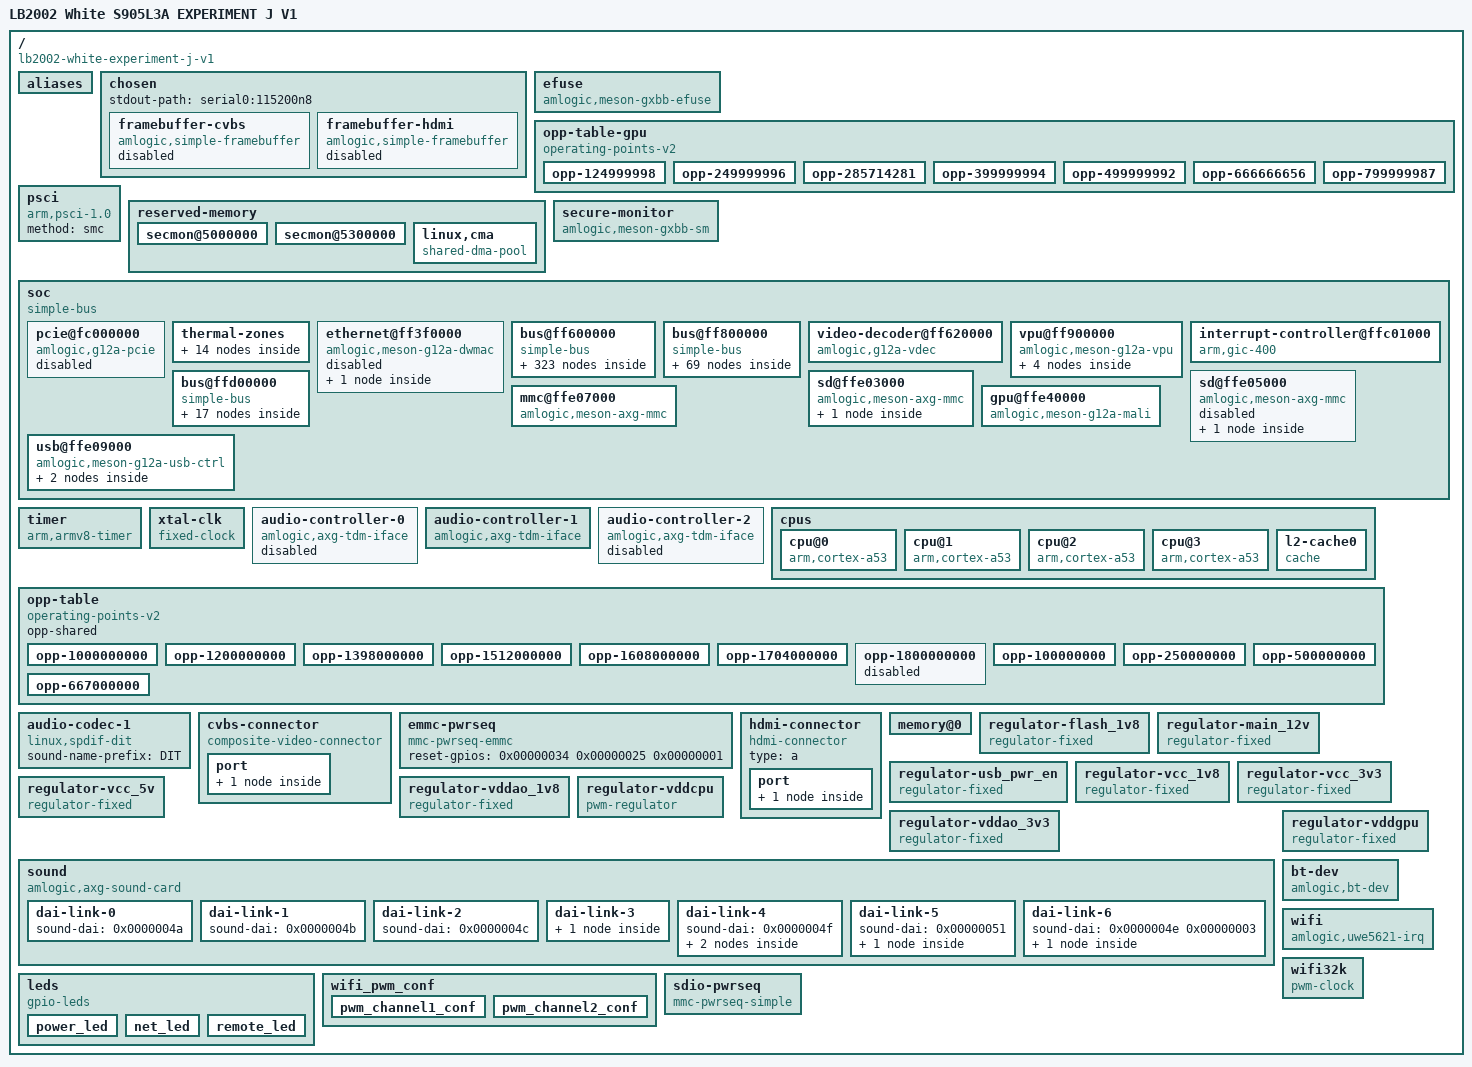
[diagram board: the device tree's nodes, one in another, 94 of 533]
/dts-v1/;
// version:		17
// last_comp_version:	16
// boot_cpuid_phys:	0x0

/ {
    interrupt-parent = <0x00000001>;
    #address-cells = <0x00000002>;
    #size-cells = <0x00000002>;
    model = "LB2002 White S905L3A EXPERIMENT J V1";
    compatible = "lb2002-white-experiment-j-v1", "lb2002-white-experiment-h-v1", "lb2002-white-experiment-g-v1", "m401a", "amlogic,g12a";
    amlogic-dt-id = "lb2002_m401a_experiment_j_v1_2g";
    aliases {
        ethernet0 = "/soc/ethernet@ff3f0000";
        serial1 = "/soc/bus@ffd00000/serial@24000";
        serial0 = "/soc/bus@ff800000/serial@3000";
        mmc2 = "/soc/mmc@ffe07000";
        mmc0 = "/soc/sd@ffe03000";
        mmc1 = "/soc/sd@ffe05000";
        sd_emmc_a = "/soc/sd@ffe03000";
        sd_emmc_b = "/soc/sd@ffe05000";
    };
    chosen {
        #address-cells = <0x00000002>;
        #size-cells = <0x00000002>;
        ranges;
        stdout-path = "serial0:115200n8";
        framebuffer-cvbs {
            compatible = "amlogic,simple-framebuffer", "simple-framebuffer";
            amlogic,pipeline = "vpu-cvbs";
            clocks = <0x00000002 0x000000a8 0x00000002 0x00000035 0x00000002 0x0000003a>;
            status = "disabled";
            power-domains = <0x00000003 0x00000000>;
            phandle = <0x00000053>;
        };
        framebuffer-hdmi {
            compatible = "amlogic,simple-framebuffer", "simple-framebuffer";
            amlogic,pipeline = "vpu-hdmi";
            clocks = <0x00000002 0x000000a8 0x00000002 0x00000035 0x00000002 0x0000003a>;
            status = "disabled";
            power-domains = <0x00000003 0x00000000>;
            phandle = <0x00000054>;
        };
    };
    efuse {
        compatible = "amlogic,meson-gxbb-efuse";
        clocks = <0x00000002 0x0000006a>;
        #address-cells = <0x00000001>;
        #size-cells = <0x00000001>;
        read-only;
        secure-monitor = <0x00000004>;
        phandle = <0x00000055>;
    };
    opp-table-gpu {
        compatible = "operating-points-v2";
        phandle = <0x00000040>;
        opp-124999998 {
            opp-hz = <0x00000000 0x0773593e>;
            opp-microvolt = <0x000c3500>;
        };
        opp-249999996 {
            opp-hz = <0x00000000 0x0ee6b27c>;
            opp-microvolt = <0x000c3500>;
        };
        opp-285714281 {
            opp-hz = <0x00000000 0x1107a769>;
            opp-microvolt = <0x000c3500>;
        };
        opp-399999994 {
            opp-hz = <0x00000000 0x17d783fa>;
            opp-microvolt = <0x000c3500>;
        };
        opp-499999992 {
            opp-hz = <0x00000000 0x1dcd64f8>;
            opp-microvolt = <0x000c3500>;
        };
        opp-666666656 {
            opp-hz = <0x00000000 0x27bc86a0>;
            opp-microvolt = <0x000c3500>;
        };
        opp-799999987 {
            opp-hz = <0x00000000 0x2faf07f3>;
            opp-microvolt = <0x000c3500>;
        };
    };
    psci {
        compatible = "arm,psci-1.0";
        method = "smc";
    };
    reserved-memory {
        #address-cells = <0x00000002>;
        #size-cells = <0x00000002>;
        ranges;
        secmon@5000000 {
            reg = <0x00000000 0x05000000 0x00000000 0x00300000>;
            no-map;
            phandle = <0x00000056>;
        };
        secmon@5300000 {
            reg = <0x00000000 0x05300000 0x00000000 0x02000000>;
            no-map;
            phandle = <0x00000057>;
        };
        linux,cma {
            compatible = "shared-dma-pool";
            reusable;
            size = <0x00000000 0x10000000>;
            alignment = <0x00000000 0x00400000>;
            linux,cma-default;
        };
    };
    secure-monitor {
        compatible = "amlogic,meson-gxbb-sm";
        phandle = <0x00000004>;
    };
    soc {
        compatible = "simple-bus";
        #address-cells = <0x00000002>;
        #size-cells = <0x00000002>;
        ranges;
        pcie@fc000000 {
            compatible = "amlogic,g12a-pcie", "snps,dw-pcie";
            reg = <0x00000000 0xfc000000 0x00000000 0x00400000 0x00000000 0xff648000 0x00000000 0x00002000 0x00000000 0xfc400000 0x00000000 0x00200000>;
            reg-names = "elbi", "cfg", "config";
            interrupts = <0x00000000 0x000000dd 0x00000004>;
            #interrupt-cells = <0x00000001>;
            interrupt-map-mask = <0x00000000 0x00000000 0x00000000 0x00000000>;
            interrupt-map = <0x00000000 0x00000000 0x00000000 0x00000000 0x00000001 0x00000000 0x000000df 0x00000004>;
            bus-range = <0x00000000 0x000000ff>;
            #address-cells = <0x00000003>;
            #size-cells = <0x00000002>;
            device_type = "pci";
            ranges = <0x81000000 0x00000000 0x00000000 0x00000000 0xfc600000 0x00000000 0x00100000 0x82000000 0x00000000 0xfc700000 0x00000000 0xfc700000 0x00000000 0x01900000>;
            clocks = <0x00000002 0x00000030 0x00000002 0x0000002d 0x00000002 0x000000c9>;
            clock-names = "general", "pclk", "port";
            resets = <0x00000005 0x0000000c 0x00000005 0x0000000f>;
            reset-names = "port", "apb";
            num-lanes = <0x00000001>;
            phys = <0x00000006 0x00000002>;
            phy-names = "pcie";
            status = "disabled";
            phandle = <0x00000058>;
        };
        thermal-zones {
            cpu-thermal {
                polling-delay = <0x000003e8>;
                polling-delay-passive = <0x00000064>;
                thermal-sensors = <0x00000007>;
                phandle = <0x00000059>;
                trips {
                    cpu-passive {
                        temperature = <0x00014c08>;
                        hysteresis = <0x000007d0>;
                        type = "passive";
                        phandle = <0x00000008>;
                    };
                    cpu-hot {
                        temperature = <0x00017318>;
                        hysteresis = <0x000007d0>;
                        type = "hot";
                        phandle = <0x0000000d>;
                    };
                    cpu-critical {
                        temperature = <0x0001adb0>;
                        hysteresis = <0x000007d0>;
                        type = "critical";
                        phandle = <0x0000005a>;
                    };
                };
                cooling-maps {
                    map0 {
                        trip = <0x00000008>;
                        cooling-device = <0x00000009 0xffffffff 0xffffffff 0x0000000a 0xffffffff 0xffffffff 0x0000000b 0xffffffff 0xffffffff 0x0000000c 0xffffffff 0xffffffff>;
                    };
                    map1 {
                        trip = <0x0000000d>;
                        cooling-device = <0x00000009 0xffffffff 0xffffffff 0x0000000a 0xffffffff 0xffffffff 0x0000000b 0xffffffff 0xffffffff 0x0000000c 0xffffffff 0xffffffff>;
                    };
                };
            };
            ddr-thermal {
                polling-delay = <0x000003e8>;
                polling-delay-passive = <0x00000064>;
                thermal-sensors = <0x0000000e>;
                phandle = <0x0000005b>;
                trips {
                    ddr-passive {
                        temperature = <0x00014c08>;
                        hysteresis = <0x000007d0>;
                        type = "passive";
                        phandle = <0x0000000f>;
                    };
                    ddr-critical {
                        temperature = <0x0001adb0>;
                        hysteresis = <0x000007d0>;
                        type = "critical";
                        phandle = <0x0000005c>;
                    };
                };
                cooling-maps {
                    map {
                        trip = <0x0000000f>;
                        cooling-device = <0x00000010 0xffffffff 0xffffffff>;
                    };
                };
            };
        };
        ethernet@ff3f0000 {
            compatible = "amlogic,meson-g12a-dwmac", "snps,dwmac-3.70a", "snps,dwmac";
            reg = <0x00000000 0xff3f0000 0x00000000 0x00010000 0x00000000 0xff634540 0x00000000 0x00000008>;
            interrupts = <0x00000000 0x00000008 0x00000004>;
            interrupt-names = "macirq";
            clocks = <0x00000002 0x00000026 0x00000002 0x00000002 0x00000002 0x0000000d 0x00000002 0x00000002>;
            clock-names = "stmmaceth", "clkin0", "clkin1", "timing-adjustment";
            rx-fifo-depth = <0x00001000>;
            tx-fifo-depth = <0x00000800>;
            status = "disabled";
            power-domains = <0x00000003 0x00000001>;
            phy-handle = <0x00000011>;
            phy-mode = "rmii";
            phandle = <0x0000005d>;
            mdio {
                #address-cells = <0x00000001>;
                #size-cells = <0x00000000>;
                compatible = "snps,dwmac-mdio";
                phandle = <0x0000001b>;
            };
        };
        bus@ff600000 {
            compatible = "simple-bus";
            reg = <0x00000000 0xff600000 0x00000000 0x00200000>;
            #address-cells = <0x00000002>;
            #size-cells = <0x00000002>;
            ranges = <0x00000000 0x00000000 0x00000000 0xff600000 0x00000000 0x00200000>;
            phandle = <0x0000005e>;
            hdmi-tx@0 {
                compatible = "amlogic,meson-g12a-dw-hdmi";
                reg = <0x00000000 0x00000000 0x00000000 0x00010000>;
                interrupts = <0x00000000 0x00000039 0x00000001>;
                resets = <0x00000005 0x00000013 0x00000005 0x00000042 0x00000005 0x0000004f>;
                reset-names = "hdmitx_apb", "hdmitx", "hdmitx_phy";
                clocks = <0x00000002 0x000000a8 0x00000002 0x00000035 0x00000002 0x0000003a>;
                clock-names = "isfr", "iahb", "venci";
                #address-cells = <0x00000001>;
                #size-cells = <0x00000000>;
                #sound-dai-cells = <0x00000000>;
                status = "okay";
                pinctrl-0 = <0x00000012 0x00000013>;
                pinctrl-names = "default";
                hdmi-supply = <0x00000014>;
                phandle = <0x00000022>;
                port@0 {
                    reg = <0x00000000>;
                    phandle = <0x0000005f>;
                    endpoint {
                        remote-endpoint = <0x00000015>;
                        phandle = <0x00000029>;
                    };
                };
                port@1 {
                    reg = <0x00000001>;
                    phandle = <0x00000060>;
                    endpoint {
                        remote-endpoint = <0x00000016>;
                        phandle = <0x00000046>;
                    };
                };
            };
            bus@30000 {
                compatible = "simple-bus";
                reg = <0x00000000 0x00030000 0x00000000 0x00002000>;
                #address-cells = <0x00000002>;
                #size-cells = <0x00000002>;
                ranges = <0x00000000 0x00000000 0x00000000 0x00030000 0x00000000 0x00002000>;
                phandle = <0x00000061>;
                rng@218 {
                    compatible = "amlogic,meson-rng";
                    reg = <0x00000000 0x00000218 0x00000000 0x00000004>;
                    clocks = <0x00000002 0x0000001b>;
                    clock-names = "core";
                    phandle = <0x00000062>;
                };
            };
            audio-controller@32000 {
                compatible = "amlogic,t9015";
                reg = <0x00000000 0x00032000 0x00000000 0x00000014>;
                #sound-dai-cells = <0x00000000>;
                sound-name-prefix = "ACODEC";
                clocks = <0x00000002 0x00000024>;
                clock-names = "pclk";
                resets = <0x00000005 0x0000003d>;
                status = "disabled";
                phandle = <0x00000063>;
            };
            bus@34400 {
                compatible = "simple-bus";
                reg = <0x00000000 0x00034400 0x00000000 0x00000400>;
                #address-cells = <0x00000002>;
                #size-cells = <0x00000002>;
                ranges = <0x00000000 0x00000000 0x00000000 0x00034400 0x00000000 0x00000400>;
                phandle = <0x00000064>;
                pinctrl@40 {
                    compatible = "amlogic,meson-g12a-periphs-pinctrl";
                    #address-cells = <0x00000002>;
                    #size-cells = <0x00000002>;
                    ranges;
                    phandle = <0x00000017>;
                    bank@40 {
                        reg = <0x00000000 0x00000040 0x00000000 0x0000004c 0x00000000 0x000000e8 0x00000000 0x00000018 0x00000000 0x00000120 0x00000000 0x00000018 0x00000000 0x000002c0 0x00000000 0x00000040 0x00000000 0x00000340 0x00000000 0x0000001c>;
                        reg-names = "gpio", "pull", "pull-enable", "mux", "ds";
                        gpio-controller;
                        #gpio-cells = <0x00000002>;
                        gpio-ranges = <0x00000017 0x00000000 0x00000000 0x00000056>;
                        phandle = <0x00000034>;
                    };
                    cec_ao_a_h {
                        phandle = <0x00000021>;
                        mux {
                            groups = "cec_ao_a_h";
                            function = "cec_ao_a_h";
                            bias-disable;
                        };
                    };
                    cec_ao_b_h {
                        phandle = <0x00000023>;
                        mux {
                            groups = "cec_ao_b_h";
                            function = "cec_ao_b_h";
                            bias-disable;
                        };
                    };
                    emmc-ctrl {
                        phandle = <0x00000036>;
                        mux-0 {
                            groups = "emmc_cmd";
                            function = "emmc";
                            bias-pull-up;
                            drive-strength-microamp = <0x00000fa0>;
                        };
                        mux-1 {
                            groups = "emmc_clk";
                            function = "emmc";
                            bias-disable;
                            drive-strength-microamp = <0x00000fa0>;
                        };
                    };
                    emmc-data-4b {
                        phandle = <0x00000065>;
                        mux-0 {
                            groups = "emmc_nand_d0", "emmc_nand_d1", "emmc_nand_d2", "emmc_nand_d3";
                            function = "emmc";
                            bias-pull-up;
                            drive-strength-microamp = <0x00000fa0>;
                        };
                    };
                    emmc-data-8b {
                        phandle = <0x00000037>;
                        mux-0 {
                            groups = "emmc_nand_d0", "emmc_nand_d1", "emmc_nand_d2", "emmc_nand_d3", "emmc_nand_d4", "emmc_nand_d5", "emmc_nand_d6", "emmc_nand_d7";
                            function = "emmc";
                            bias-pull-up;
                            drive-strength-microamp = <0x00000fa0>;
                        };
                    };
                    emmc-ds {
                        phandle = <0x00000038>;
                        mux {
                            groups = "emmc_nand_ds";
                            function = "emmc";
                            bias-pull-down;
                            drive-strength-microamp = <0x00000fa0>;
                        };
                    };
                    emmc_clk_gate {
                        phandle = <0x00000039>;
                        mux {
                            groups = "BOOT_8";
                            function = "gpio_periphs";
                            bias-pull-down;
                            drive-strength-microamp = <0x00000fa0>;
                        };
                    };
                    hdmitx_ddc {
                        phandle = <0x00000013>;
                        mux {
                            groups = "hdmitx_sda", "hdmitx_sck";
                            function = "hdmitx";
                            bias-disable;
                            drive-strength-microamp = <0x00000fa0>;
                        };
                    };
                    hdmitx_hpd {
                        phandle = <0x00000012>;
                        mux {
                            groups = "hdmitx_hpd_in";
                            function = "hdmitx";
                            bias-disable;
                        };
                    };
                    i2c0-sda-c {
                        phandle = <0x00000066>;
                        mux {
                            groups = "i2c0_sda_c";
                            function = "i2c0";
                            bias-disable;
                            drive-strength-microamp = <0x00000bb8>;
                        };
                    };
                    i2c0-sck-c {
                        phandle = <0x00000067>;
                        mux {
                            groups = "i2c0_sck_c";
                            function = "i2c0";
                            bias-disable;
                            drive-strength-microamp = <0x00000bb8>;
                        };
                    };
                    i2c0-sda-z0 {
                        phandle = <0x0000002e>;
                        mux {
                            groups = "i2c0_sda_z0";
                            function = "i2c0";
                            bias-disable;
                            drive-strength-microamp = <0x00000bb8>;
                        };
                    };
                    i2c0-sck-z1 {
                        phandle = <0x0000002f>;
                        mux {
                            groups = "i2c0_sck_z1";
                            function = "i2c0";
                            bias-disable;
                            drive-strength-microamp = <0x00000bb8>;
                        };
                    };
                    i2c0-sda-z7 {
                        phandle = <0x00000068>;
                        mux {
                            groups = "i2c0_sda_z7";
                            function = "i2c0";
                            bias-disable;
                            drive-strength-microamp = <0x00000bb8>;
                        };
                    };
                    i2c0-sda-z8 {
                        phandle = <0x00000069>;
                        mux {
                            groups = "i2c0_sda_z8";
                            function = "i2c0";
                            bias-disable;
                            drive-strength-microamp = <0x00000bb8>;
                        };
                    };
                    i2c1-sda-x {
                        phandle = <0x0000006a>;
                        mux {
                            groups = "i2c1_sda_x";
                            function = "i2c1";
                            bias-disable;
                            drive-strength-microamp = <0x00000bb8>;
                        };
                    };
                    i2c1-sck-x {
                        phandle = <0x0000006b>;
                        mux {
                            groups = "i2c1_sck_x";
                            function = "i2c1";
                            bias-disable;
                            drive-strength-microamp = <0x00000bb8>;
                        };
                    };
                    i2c1-sda-h2 {
                        phandle = <0x0000006c>;
                        mux {
                            groups = "i2c1_sda_h2";
                            function = "i2c1";
                            bias-disable;
                            drive-strength-microamp = <0x00000bb8>;
                        };
                    };
                    i2c1-sck-h3 {
                        phandle = <0x0000006d>;
                        mux {
                            groups = "i2c1_sck_h3";
                            function = "i2c1";
                            bias-disable;
                            drive-strength-microamp = <0x00000bb8>;
                        };
                    };
                    i2c1-sda-h6 {
                        phandle = <0x0000006e>;
                        mux {
                            groups = "i2c1_sda_h6";
                            function = "i2c1";
                            bias-disable;
                            drive-strength-microamp = <0x00000bb8>;
                        };
                    };
                    i2c1-sck-h7 {
                        phandle = <0x0000006f>;
                        mux {
                            groups = "i2c1_sck_h7";
                            function = "i2c1";
                            bias-disable;
                            drive-strength-microamp = <0x00000bb8>;
                        };
                    };
                    i2c2-sda-x {
                        phandle = <0x00000070>;
                        mux {
                            groups = "i2c2_sda_x";
                            function = "i2c2";
                            bias-disable;
                            drive-strength-microamp = <0x00000bb8>;
                        };
                    };
                    i2c2-sck-x {
                        phandle = <0x00000071>;
                        mux {
                            groups = "i2c2_sck_x";
                            function = "i2c2";
                            bias-disable;
                            drive-strength-microamp = <0x00000bb8>;
                        };
                    };
                    i2c2-sda-z {
                        phandle = <0x0000002c>;
                        mux {
                            groups = "i2c2_sda_z";
                            function = "i2c2";
                            bias-disable;
                            drive-strength-microamp = <0x00000bb8>;
                        };
                    };
                    i2c2-sck-z {
                        phandle = <0x0000002d>;
                        mux {
                            groups = "i2c2_sck_z";
                            function = "i2c2";
                            bias-disable;
                            drive-strength-microamp = <0x00000bb8>;
                        };
                    };
                    i2c3-sda-h {
                        phandle = <0x00000072>;
                        mux {
                            groups = "i2c3_sda_h";
                            function = "i2c3";
                            bias-disable;
                            drive-strength-microamp = <0x00000bb8>;
                        };
                    };
                    i2c3-sck-h {
                        phandle = <0x00000073>;
                        mux {
                            groups = "i2c3_sck_h";
                            function = "i2c3";
                            bias-disable;
                            drive-strength-microamp = <0x00000bb8>;
                        };
                    };
                    i2c3-sda-a {
                        phandle = <0x0000002a>;
                        mux {
                            groups = "i2c3_sda_a";
                            function = "i2c3";
                            bias-disable;
                            drive-strength-microamp = <0x00000bb8>;
                        };
                    };
                    i2c3-sck-a {
                        phandle = <0x0000002b>;
                        mux {
                            groups = "i2c3_sck_a";
                            function = "i2c3";
                            bias-disable;
                            drive-strength-microamp = <0x00000bb8>;
                        };
                    };
                    mclk0-a {
                        phandle = <0x00000074>;
                        mux {
                            groups = "mclk0_a";
                            function = "mclk0";
                            bias-disable;
                            drive-strength-microamp = <0x00000bb8>;
                        };
                    };
                    mclk1-a {
                        phandle = <0x00000075>;
                        mux {
                            groups = "mclk1_a";
                            function = "mclk1";
                            bias-disable;
                            drive-strength-microamp = <0x00000bb8>;
                        };
                    };
                    mclk1-x {
                        phandle = <0x00000076>;
                        mux {
                            groups = "mclk1_x";
                            function = "mclk1";
                            bias-disable;
                            drive-strength-microamp = <0x00000bb8>;
                        };
                    };
                    mclk1-z {
                        phandle = <0x00000077>;
                        mux {
                            groups = "mclk1_z";
                            function = "mclk1";
                            bias-disable;
                            drive-strength-microamp = <0x00000bb8>;
                        };
                    };
                    nor {
                        phandle = <0x00000078>;
                        mux {
                            groups = "nor_d", "nor_q", "nor_c", "nor_cs";
                            function = "nor";
                            bias-disable;
                        };
                    };
                    pdm-din0-a {
                        phandle = <0x00000079>;
                        mux {
                            groups = "pdm_din0_a";
                            function = "pdm";
                            bias-disable;
                        };
                    };
                    pdm-din0-c {
                        phandle = <0x0000007a>;
                        mux {
                            groups = "pdm_din0_c";
                            function = "pdm";
                            bias-disable;
                        };
                    };
                    pdm-din0-x {
                        phandle = <0x0000007b>;
                        mux {
                            groups = "pdm_din0_x";
                            function = "pdm";
                            bias-disable;
                        };
                    };
                    pdm-din0-z {
                        phandle = <0x0000007c>;
                        mux {
                            groups = "pdm_din0_z";
                            function = "pdm";
                            bias-disable;
                        };
                    };
                    pdm-din1-a {
                        phandle = <0x0000007d>;
                        mux {
                            groups = "pdm_din1_a";
                            function = "pdm";
                            bias-disable;
                        };
                    };
                    pdm-din1-c {
                        phandle = <0x0000007e>;
                        mux {
                            groups = "pdm_din1_c";
                            function = "pdm";
                            bias-disable;
                        };
                    };
                    pdm-din1-x {
                        phandle = <0x0000007f>;
                        mux {
                            groups = "pdm_din1_x";
                            function = "pdm";
                            bias-disable;
                        };
                    };
                    pdm-din1-z {
                        phandle = <0x00000080>;
                        mux {
                            groups = "pdm_din1_z";
                            function = "pdm";
                            bias-disable;
                        };
                    };
                    pdm-din2-a {
                        phandle = <0x00000081>;
                        mux {
                            groups = "pdm_din2_a";
                            function = "pdm";
                            bias-disable;
                        };
                    };
                    pdm-din2-c {
                        phandle = <0x00000082>;
                        mux {
                            groups = "pdm_din2_c";
                            function = "pdm";
                            bias-disable;
                        };
                    };
                    pdm-din2-x {
                        phandle = <0x00000083>;
                        mux {
                            groups = "pdm_din2_x";
                            function = "pdm";
                            bias-disable;
                        };
                    };
                    pdm-din2-z {
                        phandle = <0x00000084>;
                        mux {
                            groups = "pdm_din2_z";
                            function = "pdm";
                            bias-disable;
                        };
                    };
                    pdm-din3-a {
                        phandle = <0x00000085>;
                        mux {
                            groups = "pdm_din3_a";
                            function = "pdm";
                            bias-disable;
                        };
                    };
                    pdm-din3-c {
                        phandle = <0x00000086>;
                        mux {
                            groups = "pdm_din3_c";
                            function = "pdm";
                            bias-disable;
                        };
                    };
                    pdm-din3-x {
                        phandle = <0x00000087>;
                        mux {
                            groups = "pdm_din3_x";
                            function = "pdm";
                            bias-disable;
                        };
                    };
                    pdm-din3-z {
                        phandle = <0x00000088>;
                        mux {
                            groups = "pdm_din3_z";
                            function = "pdm";
                            bias-disable;
                        };
                    };
                    pdm-dclk-a {
                        phandle = <0x00000089>;
                        mux {
                            groups = "pdm_dclk_a";
                            function = "pdm";
                            bias-disable;
                            drive-strength-microamp = <0x000001f4>;
                        };
                    };
                    pdm-dclk-c {
                        phandle = <0x0000008a>;
                        mux {
                            groups = "pdm_dclk_c";
                            function = "pdm";
                            bias-disable;
                            drive-strength-microamp = <0x000001f4>;
                        };
                    };
                    pdm-dclk-x {
                        phandle = <0x0000008b>;
                        mux {
                            groups = "pdm_dclk_x";
                            function = "pdm";
                            bias-disable;
                            drive-strength-microamp = <0x000001f4>;
                        };
                    };
                    pdm-dclk-z {
                        phandle = <0x0000008c>;
                        mux {
                            groups = "pdm_dclk_z";
                            function = "pdm";
                            bias-disable;
                            drive-strength-microamp = <0x000001f4>;
                        };
                    };
                    pwm-a {
                        phandle = <0x0000008d>;
                        mux {
                            groups = "pwm_a";
                            function = "pwm_a";
                            bias-disable;
                        };
                    };
                    pwm-b-x7 {
                        phandle = <0x0000008e>;
                        mux {
                            groups = "pwm_b_x7";
                            function = "pwm_b";
                            bias-disable;
                        };
                    };
                    pwm-b-x19 {
                        phandle = <0x0000008f>;
                        mux {
                            groups = "pwm_b_x19";
                            function = "pwm_b";
                            bias-disable;
                        };
                    };
                    pwm-c-c {
                        phandle = <0x00000090>;
                        mux {
                            groups = "pwm_c_c";
                            function = "pwm_c";
                            bias-disable;
                        };
                    };
                    pwm-c-x5 {
                        phandle = <0x00000091>;
                        mux {
                            groups = "pwm_c_x5";
                            function = "pwm_c";
                            bias-disable;
                        };
                    };
                    pwm-c-x8 {
                        phandle = <0x00000092>;
                        mux {
                            groups = "pwm_c_x8";
                            function = "pwm_c";
                            bias-disable;
                        };
                    };
                    pwm-d-x3 {
                        phandle = <0x00000093>;
                        mux {
                            groups = "pwm_d_x3";
                            function = "pwm_d";
                            bias-disable;
                        };
                    };
                    pwm-d-x6 {
                        phandle = <0x00000094>;
                        mux {
                            groups = "pwm_d_x6";
                            function = "pwm_d";
                            bias-disable;
                        };
                    };
                    pwm-e {
                        phandle = <0x00000095>;
                        mux {
                            groups = "pwm_e";
                            function = "pwm_e";
                            bias-disable;
                        };
                    };
                    pwm-f-x {
                        phandle = <0x00000096>;
                        mux {
                            groups = "pwm_f_x";
                            function = "pwm_f";
                            bias-disable;
                        };
                    };
                    pwm-f-h {
                        phandle = <0x00000097>;
                        mux {
                            groups = "pwm_f_h";
                            function = "pwm_f";
                            bias-disable;
                        };
                    };
                    sdcard_c {
                        phandle = <0x00000032>;
                        mux-0 {
                            groups = "sdcard_d0_c", "sdcard_d1_c", "sdcard_d2_c", "sdcard_d3_c", "sdcard_cmd_c";
                            function = "sdcard";
                            bias-pull-up;
                            drive-strength-microamp = <0x00000fa0>;
                        };
                        mux-1 {
                            groups = "sdcard_clk_c";
                            function = "sdcard";
                            bias-disable;
                            drive-strength-microamp = <0x00000fa0>;
                        };
                    };
                    sdcard_clk_gate_c {
                        phandle = <0x00000033>;
                        mux {
                            groups = "GPIOC_4";
                            function = "gpio_periphs";
                            bias-pull-down;
                            drive-strength-microamp = <0x00000fa0>;
                        };
                    };
                    sdcard_z {
                        phandle = <0x00000098>;
                        mux-0 {
                            groups = "sdcard_d0_z", "sdcard_d1_z", "sdcard_d2_z", "sdcard_d3_z", "sdcard_cmd_z";
                            function = "sdcard";
                            bias-pull-up;
                            drive-strength-microamp = <0x00000fa0>;
                        };
                        mux-1 {
                            groups = "sdcard_clk_z";
                            function = "sdcard";
                            bias-disable;
                            drive-strength-microamp = <0x00000fa0>;
                        };
                    };
                    sdcard_clk_gate_z {
                        phandle = <0x00000099>;
                        mux {
                            groups = "GPIOZ_6";
                            function = "gpio_periphs";
                            bias-pull-down;
                            drive-strength-microamp = <0x00000fa0>;
                        };
                    };
                    sdio {
                        phandle = <0x0000009a>;
                        mux {
                            groups = "sdio_d0", "sdio_d1", "sdio_d2", "sdio_d3", "sdio_clk", "sdio_cmd";
                            function = "sdio";
                            bias-disable;
                            drive-strength-microamp = <0x00000fa0>;
                        };
                    };
                    sdio_clk_gate {
                        phandle = <0x0000009b>;
                        mux {
                            groups = "GPIOX_4";
                            function = "gpio_periphs";
                            bias-pull-down;
                            drive-strength-microamp = <0x00000fa0>;
                        };
                    };
                    spdif-in-a10 {
                        phandle = <0x0000009c>;
                        mux {
                            groups = "spdif_in_a10";
                            function = "spdif_in";
                            bias-disable;
                        };
                    };
                    spdif-in-a12 {
                        phandle = <0x0000009d>;
                        mux {
                            groups = "spdif_in_a12";
                            function = "spdif_in";
                            bias-disable;
                        };
                    };
                    spdif-in-h {
                        phandle = <0x0000009e>;
                        mux {
                            groups = "spdif_in_h";
                            function = "spdif_in";
                            bias-disable;
                        };
                    };
                    spdif-out-h {
                        phandle = <0x0000001e>;
                        mux {
                            groups = "spdif_out_h";
                            function = "spdif_out";
                            drive-strength-microamp = <0x000001f4>;
                            bias-disable;
                        };
                    };
                    spdif-out-a11 {
                        phandle = <0x0000009f>;
                        mux {
                            groups = "spdif_out_a11";
                            function = "spdif_out";
                            drive-strength-microamp = <0x000001f4>;
                            bias-disable;
                        };
                    };
                    spdif-out-a13 {
                        phandle = <0x000000a0>;
                        mux {
                            groups = "spdif_out_a13";
                            function = "spdif_out";
                            drive-strength-microamp = <0x000001f4>;
                            bias-disable;
                        };
                    };
                    spicc0-x {
                        phandle = <0x000000a1>;
                        mux {
                            groups = "spi0_mosi_x", "spi0_miso_x", "spi0_clk_x";
                            function = "spi0";
                            drive-strength-microamp = <0x00000fa0>;
                            bias-disable;
                        };
                    };
                    spicc0-ss0-x {
                        phandle = <0x000000a2>;
                        mux {
                            groups = "spi0_ss0_x";
                            function = "spi0";
                            drive-strength-microamp = <0x00000fa0>;
                            bias-disable;
                        };
                    };
                    spicc0-c {
                        phandle = <0x000000a3>;
                        mux {
                            groups = "spi0_mosi_c", "spi0_miso_c", "spi0_ss0_c", "spi0_clk_c";
                            function = "spi0";
                            drive-strength-microamp = <0x00000fa0>;
                            bias-disable;
                        };
                    };
                    spicc1 {
                        phandle = <0x000000a4>;
                        mux {
                            groups = "spi1_mosi", "spi1_miso", "spi1_clk";
                            function = "spi1";
                            drive-strength-microamp = <0x00000fa0>;
                        };
                    };
                    spicc1-ss0 {
                        phandle = <0x000000a5>;
                        mux {
                            groups = "spi1_ss0";
                            function = "spi1";
                            drive-strength-microamp = <0x00000fa0>;
                            bias-disable;
                        };
                    };
                    tdm-a-din0 {
                        phandle = <0x000000a6>;
                        mux {
                            groups = "tdm_a_din0";
                            function = "tdm_a";
                            bias-disable;
                        };
                    };
                    tdm-a-din1 {
                        phandle = <0x000000a7>;
                        mux {
                            groups = "tdm_a_din1";
                            function = "tdm_a";
                            bias-disable;
                        };
                    };
                    tdm-a-dout0 {
                        phandle = <0x000000a8>;
                        mux {
                            groups = "tdm_a_dout0";
                            function = "tdm_a";
                            bias-disable;
                            drive-strength-microamp = <0x00000bb8>;
                        };
                    };
                    tdm-a-dout1 {
                        phandle = <0x000000a9>;
                        mux {
                            groups = "tdm_a_dout1";
                            function = "tdm_a";
                            bias-disable;
                            drive-strength-microamp = <0x00000bb8>;
                        };
                    };
                    tdm-a-fs {
                        phandle = <0x000000aa>;
                        mux {
                            groups = "tdm_a_fs";
                            function = "tdm_a";
                            bias-disable;
                            drive-strength-microamp = <0x00000bb8>;
                        };
                    };
                    tdm-a-sclk {
                        phandle = <0x000000ab>;
                        mux {
                            groups = "tdm_a_sclk";
                            function = "tdm_a";
                            bias-disable;
                            drive-strength-microamp = <0x00000bb8>;
                        };
                    };
                    tdm-a-slv-fs {
                        phandle = <0x000000ac>;
                        mux {
                            groups = "tdm_a_slv_fs";
                            function = "tdm_a";
                            bias-disable;
                        };
                    };
                    tdm-a-slv-sclk {
                        phandle = <0x000000ad>;
                        mux {
                            groups = "tdm_a_slv_sclk";
                            function = "tdm_a";
                            bias-disable;
                        };
                    };
                    tdm-b-din0 {
                        phandle = <0x000000ae>;
                        mux {
                            groups = "tdm_b_din0";
                            function = "tdm_b";
                            bias-disable;
                        };
                    };
                    tdm-b-din1 {
                        phandle = <0x000000af>;
                        mux {
                            groups = "tdm_b_din1";
                            function = "tdm_b";
                            bias-disable;
                        };
                    };
                    tdm-b-din2 {
                        phandle = <0x000000b0>;
                        mux {
                            groups = "tdm_b_din2";
                            function = "tdm_b";
                            bias-disable;
                        };
                    };
                    tdm-b-din3-a {
                        phandle = <0x000000b1>;
                        mux {
                            groups = "tdm_b_din3_a";
                            function = "tdm_b";
                            bias-disable;
                        };
                    };
                    tdm-b-din3-h {
                        phandle = <0x000000b2>;
                        mux {
                            groups = "tdm_b_din3_h";
                            function = "tdm_b";
                            bias-disable;
                        };
                    };
                    tdm-b-dout0 {
                        phandle = <0x000000b3>;
                        mux {
                            groups = "tdm_b_dout0";
                            function = "tdm_b";
                            bias-disable;
                            drive-strength-microamp = <0x00000bb8>;
                        };
                    };
                    tdm-b-dout1 {
                        phandle = <0x000000b4>;
                        mux {
                            groups = "tdm_b_dout1";
                            function = "tdm_b";
                            bias-disable;
                            drive-strength-microamp = <0x00000bb8>;
                        };
                    };
                    tdm-b-dout2 {
                        phandle = <0x000000b5>;
                        mux {
                            groups = "tdm_b_dout2";
                            function = "tdm_b";
                            bias-disable;
                            drive-strength-microamp = <0x00000bb8>;
                        };
                    };
                    tdm-b-dout3-a {
                        phandle = <0x000000b6>;
                        mux {
                            groups = "tdm_b_dout3_a";
                            function = "tdm_b";
                            bias-disable;
                            drive-strength-microamp = <0x00000bb8>;
                        };
                    };
                    tdm-b-dout3-h {
                        phandle = <0x000000b7>;
                        mux {
                            groups = "tdm_b_dout3_h";
                            function = "tdm_b";
                            bias-disable;
                            drive-strength-microamp = <0x00000bb8>;
                        };
                    };
                    tdm-b-fs {
                        phandle = <0x000000b8>;
                        mux {
                            groups = "tdm_b_fs";
                            function = "tdm_b";
                            bias-disable;
                            drive-strength-microamp = <0x00000bb8>;
                        };
                    };
                    tdm-b-sclk {
                        phandle = <0x000000b9>;
                        mux {
                            groups = "tdm_b_sclk";
                            function = "tdm_b";
                            bias-disable;
                            drive-strength-microamp = <0x00000bb8>;
                        };
                    };
                    tdm-b-slv-fs {
                        phandle = <0x000000ba>;
                        mux {
                            groups = "tdm_b_slv_fs";
                            function = "tdm_b";
                            bias-disable;
                        };
                    };
                    tdm-b-slv-sclk {
                        phandle = <0x000000bb>;
                        mux {
                            groups = "tdm_b_slv_sclk";
                            function = "tdm_b";
                            bias-disable;
                        };
                    };
                    tdm-c-din0-a {
                        phandle = <0x000000bc>;
                        mux {
                            groups = "tdm_c_din0_a";
                            function = "tdm_c";
                            bias-disable;
                        };
                    };
                    tdm-c-din0-z {
                        phandle = <0x000000bd>;
                        mux {
                            groups = "tdm_c_din0_z";
                            function = "tdm_c";
                            bias-disable;
                        };
                    };
                    tdm-c-din1-a {
                        phandle = <0x000000be>;
                        mux {
                            groups = "tdm_c_din1_a";
                            function = "tdm_c";
                            bias-disable;
                        };
                    };
                    tdm-c-din1-z {
                        phandle = <0x000000bf>;
                        mux {
                            groups = "tdm_c_din1_z";
                            function = "tdm_c";
                            bias-disable;
                        };
                    };
                    tdm-c-din2-a {
                        phandle = <0x000000c0>;
                        mux {
                            groups = "tdm_c_din2_a";
                            function = "tdm_c";
                            bias-disable;
                        };
                    };
                    eth-leds {
                        phandle = <0x000000c1>;
                        mux {
                            groups = "eth_link_led", "eth_act_led";
                            function = "eth";
                            bias-disable;
                        };
                    };
                    eth {
                        phandle = <0x000000c2>;
                        mux {
                            groups = "eth_mdio", "eth_mdc", "eth_rgmii_rx_clk", "eth_rx_dv", "eth_rxd0", "eth_rxd1", "eth_txen", "eth_txd0", "eth_txd1";
                            function = "eth";
                            drive-strength-microamp = <0x00000fa0>;
                            bias-disable;
                        };
                    };
                    eth-rgmii {
                        phandle = <0x000000c3>;
                        mux {
                            groups = "eth_rxd2_rgmii", "eth_rxd3_rgmii", "eth_rgmii_tx_clk", "eth_txd2_rgmii", "eth_txd3_rgmii";
                            function = "eth";
                            drive-strength-microamp = <0x00000fa0>;
                            bias-disable;
                        };
                    };
                    tdm-c-din2-z {
                        phandle = <0x000000c4>;
                        mux {
                            groups = "tdm_c_din2_z";
                            function = "tdm_c";
                            bias-disable;
                        };
                    };
                    tdm-c-din3-a {
                        phandle = <0x000000c5>;
                        mux {
                            groups = "tdm_c_din3_a";
                            function = "tdm_c";
                            bias-disable;
                        };
                    };
                    tdm-c-din3-z {
                        phandle = <0x000000c6>;
                        mux {
                            groups = "tdm_c_din3_z";
                            function = "tdm_c";
                            bias-disable;
                        };
                    };
                    tdm-c-dout0-a {
                        phandle = <0x000000c7>;
                        mux {
                            groups = "tdm_c_dout0_a";
                            function = "tdm_c";
                            bias-disable;
                            drive-strength-microamp = <0x00000bb8>;
                        };
                    };
                    tdm-c-dout0-z {
                        phandle = <0x000000c8>;
                        mux {
                            groups = "tdm_c_dout0_z";
                            function = "tdm_c";
                            bias-disable;
                            drive-strength-microamp = <0x00000bb8>;
                        };
                    };
                    tdm-c-dout1-a {
                        phandle = <0x000000c9>;
                        mux {
                            groups = "tdm_c_dout1_a";
                            function = "tdm_c";
                            bias-disable;
                            drive-strength-microamp = <0x00000bb8>;
                        };
                    };
                    tdm-c-dout1-z {
                        phandle = <0x000000ca>;
                        mux {
                            groups = "tdm_c_dout1_z";
                            function = "tdm_c";
                            bias-disable;
                            drive-strength-microamp = <0x00000bb8>;
                        };
                    };
                    tdm-c-dout2-a {
                        phandle = <0x000000cb>;
                        mux {
                            groups = "tdm_c_dout2_a";
                            function = "tdm_c";
                            bias-disable;
                            drive-strength-microamp = <0x00000bb8>;
                        };
                    };
                    tdm-c-dout2-z {
                        phandle = <0x000000cc>;
                        mux {
                            groups = "tdm_c_dout2_z";
                            function = "tdm_c";
                            bias-disable;
                            drive-strength-microamp = <0x00000bb8>;
                        };
                    };
                    tdm-c-dout3-a {
                        phandle = <0x000000cd>;
                        mux {
                            groups = "tdm_c_dout3_a";
                            function = "tdm_c";
                            bias-disable;
                            drive-strength-microamp = <0x00000bb8>;
                        };
                    };
                    tdm-c-dout3-z {
                        phandle = <0x000000ce>;
                        mux {
                            groups = "tdm_c_dout3_z";
                            function = "tdm_c";
                            bias-disable;
                            drive-strength-microamp = <0x00000bb8>;
                        };
                    };
                    tdm-c-fs-a {
                        phandle = <0x000000cf>;
                        mux {
                            groups = "tdm_c_fs_a";
                            function = "tdm_c";
                            bias-disable;
                            drive-strength-microamp = <0x00000bb8>;
                        };
                    };
                    tdm-c-fs-z {
                        phandle = <0x000000d0>;
                        mux {
                            groups = "tdm_c_fs_z";
                            function = "tdm_c";
                            bias-disable;
                            drive-strength-microamp = <0x00000bb8>;
                        };
                    };
                    tdm-c-sclk-a {
                        phandle = <0x000000d1>;
                        mux {
                            groups = "tdm_c_sclk_a";
                            function = "tdm_c";
                            bias-disable;
                            drive-strength-microamp = <0x00000bb8>;
                        };
                    };
                    tdm-c-sclk-z {
                        phandle = <0x000000d2>;
                        mux {
                            groups = "tdm_c_sclk_z";
                            function = "tdm_c";
                            bias-disable;
                            drive-strength-microamp = <0x00000bb8>;
                        };
                    };
                    tdm-c-slv-fs-a {
                        phandle = <0x000000d3>;
                        mux {
                            groups = "tdm_c_slv_fs_a";
                            function = "tdm_c";
                            bias-disable;
                        };
                    };
                    tdm-c-slv-fs-z {
                        phandle = <0x000000d4>;
                        mux {
                            groups = "tdm_c_slv_fs_z";
                            function = "tdm_c";
                            bias-disable;
                        };
                    };
                    tdm-c-slv-sclk-a {
                        phandle = <0x000000d5>;
                        mux {
                            groups = "tdm_c_slv_sclk_a";
                            function = "tdm_c";
                            bias-disable;
                        };
                    };
                    tdm-c-slv-sclk-z {
                        phandle = <0x000000d6>;
                        mux {
                            groups = "tdm_c_slv_sclk_z";
                            function = "tdm_c";
                            bias-disable;
                        };
                    };
                    uart-a {
                        phandle = <0x00000030>;
                        mux {
                            groups = "uart_a_tx", "uart_a_rx";
                            function = "uart_a";
                            bias-disable;
                        };
                    };
                    uart-a-cts-rts {
                        phandle = <0x00000031>;
                        mux {
                            groups = "uart_a_cts", "uart_a_rts";
                            function = "uart_a";
                            bias-disable;
                        };
                    };
                    uart-b {
                        phandle = <0x000000d7>;
                        mux {
                            groups = "uart_b_tx", "uart_b_rx";
                            function = "uart_b";
                            bias-disable;
                        };
                    };
                    uart-c {
                        phandle = <0x000000d8>;
                        mux {
                            groups = "uart_c_tx", "uart_c_rx";
                            function = "uart_c";
                            bias-disable;
                        };
                    };
                    uart-c-cts-rts {
                        phandle = <0x000000d9>;
                        mux {
                            groups = "uart_c_cts", "uart_c_rts";
                            function = "uart_c";
                            bias-disable;
                        };
                    };
                };
            };
            temperature-sensor@34800 {
                compatible = "amlogic,g12a-cpu-thermal", "amlogic,g12a-thermal";
                reg = <0x00000000 0x00034800 0x00000000 0x00000050>;
                interrupts = <0x00000000 0x00000023 0x00000001>;
                clocks = <0x00000002 0x000000d4>;
                #thermal-sensor-cells = <0x00000000>;
                amlogic,ao-secure = <0x00000018>;
                phandle = <0x00000007>;
            };
            temperature-sensor@34c00 {
                compatible = "amlogic,g12a-ddr-thermal", "amlogic,g12a-thermal";
                reg = <0x00000000 0x00034c00 0x00000000 0x00000050>;
                interrupts = <0x00000000 0x00000024 0x00000001>;
                clocks = <0x00000002 0x000000d4>;
                #thermal-sensor-cells = <0x00000000>;
                amlogic,ao-secure = <0x00000018>;
                phandle = <0x0000000e>;
            };
            phy@36000 {
                compatible = "amlogic,g12a-usb2-phy";
                reg = <0x00000000 0x00036000 0x00000000 0x00002000>;
                clocks = <0x00000019>;
                clock-names = "xtal";
                resets = <0x00000005 0x00000030>;
                reset-names = "phy";
                #phy-cells = <0x00000000>;
                phy-supply = <0x00000014>;
                phandle = <0x0000003d>;
            };
            bus@38000 {
                compatible = "simple-bus";
                #address-cells = <0x00000002>;
                #size-cells = <0x00000002>;
                ranges = <0x00000000 0x00000000 0x00000000 0x00038000 0x00000000 0x00002000>;
                phandle = <0x000000da>;
                video-lut@48 {
                    compatible = "amlogic,canvas";
                    reg = <0x00000000 0x00000048 0x00000000 0x00000014>;
                    phandle = <0x00000027>;
                };
            };
            phy@3a000 {
                compatible = "amlogic,g12a-usb2-phy";
                reg = <0x00000000 0x0003a000 0x00000000 0x00002000>;
                clocks = <0x00000019>;
                clock-names = "xtal";
                resets = <0x00000005 0x00000031>;
                reset-names = "phy";
                #phy-cells = <0x00000000>;
                phy-supply = <0x00000014>;
                phandle = <0x0000003e>;
            };
            bus@3c000 {
                compatible = "simple-bus";
                reg = <0x00000000 0x0003c000 0x00000000 0x00001400>;
                #address-cells = <0x00000002>;
                #size-cells = <0x00000002>;
                ranges = <0x00000000 0x00000000 0x00000000 0x0003c000 0x00000000 0x00001400>;
                phandle = <0x000000db>;
                system-controller@0 {
                    compatible = "amlogic,meson-gx-hhi-sysctrl", "simple-mfd", "syscon";
                    reg = <0x00000000 0x00000000 0x00000000 0x00000400>;
                    phandle = <0x000000dc>;
                    clock-controller {
                        compatible = "amlogic,g12a-clkc";
                        #clock-cells = <0x00000001>;
                        clocks = <0x00000019>;
                        clock-names = "xtal";
                        phandle = <0x00000002>;
                    };
                    power-controller {
                        compatible = "amlogic,meson-g12a-pwrc";
                        #power-domain-cells = <0x00000001>;
                        amlogic,ao-sysctrl = <0x0000001a>;
                        resets = <0x00000005 0x00000005 0x00000005 0x0000000a 0x00000005 0x0000000d 0x00000005 0x00000025 0x00000005 0x00000085 0x00000005 0x00000086 0x00000005 0x00000087 0x00000005 0x00000089 0x00000005 0x0000008c 0x00000005 0x0000008d 0x00000005 0x000000e7>;
                        reset-names = "viu", "venc", "vcbus", "bt656", "rdma", "venci", "vencp", "vdac", "vdi6", "vencl", "vid_lock";
                        clocks = <0x00000002 0x00000074 0x00000002 0x0000007c>;
                        clock-names = "vpu", "vapb";
                        assigned-clocks = <0x00000002 0x0000006e 0x00000002 0x00000070 0x00000002 0x00000074 0x00000002 0x00000075 0x00000002 0x00000077 0x00000002 0x0000007b>;
                        assigned-clock-parents = <0x00000002 0x00000003 0x00000000 0x00000002 0x00000070 0x00000002 0x00000004 0x00000000 0x00000002 0x00000077>;
                        assigned-clock-rates = <0x00000000 0x27bc86aa 0x00000000 0x00000000 0x0ee6b280 0x00000000>;
                        phandle = <0x00000003>;
                    };
                };
            };
            phy@46000 {
                compatible = "amlogic,g12a-usb3-pcie-phy";
                reg = <0x00000000 0x00046000 0x00000000 0x00002000>;
                clocks = <0x00000002 0x000000c9>;
                clock-names = "ref_clk";
                resets = <0x00000005 0x0000000e>;
                reset-names = "phy";
                assigned-clocks = <0x00000002 0x000000c9>;
                assigned-clock-rates = <0x05f5e100>;
                #phy-cells = <0x00000001>;
                phandle = <0x00000006>;
            };
            mdio-multiplexer@4c000 {
                compatible = "amlogic,g12a-mdio-mux";
                reg = <0x00000000 0x0004c000 0x00000000 0x000000a4>;
                clocks = <0x00000002 0x00000013 0x00000019 0x00000002 0x000000b1>;
                clock-names = "pclk", "clkin0", "clkin1";
                mdio-parent-bus = <0x0000001b>;
                #address-cells = <0x00000001>;
                #size-cells = <0x00000000>;
                phandle = <0x000000dd>;
                mdio@0 {
                    reg = <0x00000000>;
                    #address-cells = <0x00000001>;
                    #size-cells = <0x00000000>;
                    phandle = <0x000000de>;
                };
                mdio@1 {
                    reg = <0x00000001>;
                    #address-cells = <0x00000001>;
                    #size-cells = <0x00000000>;
                    phandle = <0x000000df>;
                    ethernet-phy@8 {
                        compatible = "ethernet-phy-id0180.3301", "ethernet-phy-ieee802.3-c22";
                        interrupts = <0x00000000 0x00000009 0x00000004>;
                        reg = <0x00000008>;
                        max-speed = <0x00000064>;
                        phandle = <0x00000011>;
                    };
                };
            };
            audio-controller@40000 {
                compatible = "amlogic,g12a-pdm", "amlogic,axg-pdm";
                reg = <0x00000000 0x00040000 0x00000000 0x00000034>;
                #sound-dai-cells = <0x00000000>;
                sound-name-prefix = "PDM";
                clocks = <0x0000001c 0x0000001e 0x0000001c 0x00000039 0x0000001c 0x0000003a>;
                clock-names = "pclk", "dclk", "sysclk";
                resets = <0x0000001c 0x00000000>;
                status = "disabled";
                phandle = <0x000000e0>;
            };
            bus@42000 {
                compatible = "simple-bus";
                reg = <0x00000000 0x00042000 0x00000000 0x00002000>;
                #address-cells = <0x00000002>;
                #size-cells = <0x00000002>;
                ranges = <0x00000000 0x00000000 0x00000000 0x00042000 0x00000000 0x00002000>;
                phandle = <0x000000e1>;
                clock-controller@0 {
                    status = "okay";
                    compatible = "amlogic,g12a-audio-clkc";
                    reg = <0x00000000 0x00000000 0x00000000 0x000000b4>;
                    #clock-cells = <0x00000001>;
                    #reset-cells = <0x00000001>;
                    clocks = <0x00000002 0x00000025 0x00000002 0x0000000b 0x00000002 0x0000000c 0x00000002 0x0000000d 0x00000002 0x0000000e 0x00000002 0x0000004a 0x00000002 0x00000003 0x00000002 0x00000004 0x00000002 0x00000007>;
                    clock-names = "pclk", "mst_in0", "mst_in1", "mst_in2", "mst_in3", "mst_in4", "mst_in5", "mst_in6", "mst_in7";
                    resets = <0x00000005 0x00000041>;
                    phandle = <0x0000001c>;
                };
                audio-controller@100 {
                    compatible = "amlogic,g12a-toddr", "amlogic,axg-toddr";
                    reg = <0x00000000 0x00000100 0x00000000 0x0000002c>;
                    #sound-dai-cells = <0x00000000>;
                    sound-name-prefix = "TODDR_A";
                    interrupts = <0x00000000 0x00000094 0x00000001>;
                    clocks = <0x0000001c 0x00000029>;
                    resets = <0x0000001d 0x00000000 0x0000001c 0x00000006>;
                    reset-names = "arb", "rst";
                    amlogic,fifo-depth = <0x00000200>;
                    status = "disabled";
                    phandle = <0x000000e2>;
                };
                audio-controller@140 {
                    compatible = "amlogic,g12a-toddr", "amlogic,axg-toddr";
                    reg = <0x00000000 0x00000140 0x00000000 0x0000002c>;
                    #sound-dai-cells = <0x00000000>;
                    sound-name-prefix = "TODDR_B";
                    interrupts = <0x00000000 0x00000095 0x00000001>;
                    clocks = <0x0000001c 0x0000002a>;
                    resets = <0x0000001d 0x00000001 0x0000001c 0x00000007>;
                    reset-names = "arb", "rst";
                    amlogic,fifo-depth = <0x00000100>;
                    status = "disabled";
                    phandle = <0x000000e3>;
                };
                audio-controller@180 {
                    compatible = "amlogic,g12a-toddr", "amlogic,axg-toddr";
                    reg = <0x00000000 0x00000180 0x00000000 0x0000002c>;
                    #sound-dai-cells = <0x00000000>;
                    sound-name-prefix = "TODDR_C";
                    interrupts = <0x00000000 0x00000096 0x00000001>;
                    clocks = <0x0000001c 0x0000002b>;
                    resets = <0x0000001d 0x00000002 0x0000001c 0x00000008>;
                    reset-names = "arb", "rst";
                    amlogic,fifo-depth = <0x00000100>;
                    status = "disabled";
                    phandle = <0x000000e4>;
                };
                audio-controller@1c0 {
                    compatible = "amlogic,g12a-frddr", "amlogic,axg-frddr";
                    reg = <0x00000000 0x000001c0 0x00000000 0x0000002c>;
                    #sound-dai-cells = <0x00000000>;
                    sound-name-prefix = "FRDDR_A";
                    interrupts = <0x00000000 0x00000098 0x00000001>;
                    clocks = <0x0000001c 0x00000026>;
                    resets = <0x0000001d 0x00000003 0x0000001c 0x00000009>;
                    reset-names = "arb", "rst";
                    amlogic,fifo-depth = <0x00000200>;
                    status = "okay";
                    phandle = <0x0000004a>;
                };
                audio-controller@200 {
                    compatible = "amlogic,g12a-frddr", "amlogic,axg-frddr";
                    reg = <0x00000000 0x00000200 0x00000000 0x0000002c>;
                    #sound-dai-cells = <0x00000000>;
                    sound-name-prefix = "FRDDR_B";
                    interrupts = <0x00000000 0x00000099 0x00000001>;
                    clocks = <0x0000001c 0x00000027>;
                    resets = <0x0000001d 0x00000004 0x0000001c 0x0000000a>;
                    reset-names = "arb", "rst";
                    amlogic,fifo-depth = <0x00000100>;
                    status = "okay";
                    phandle = <0x0000004b>;
                };
                audio-controller@240 {
                    compatible = "amlogic,g12a-frddr", "amlogic,axg-frddr";
                    reg = <0x00000000 0x00000240 0x00000000 0x0000002c>;
                    #sound-dai-cells = <0x00000000>;
                    sound-name-prefix = "FRDDR_C";
                    interrupts = <0x00000000 0x0000009a 0x00000001>;
                    clocks = <0x0000001c 0x00000028>;
                    resets = <0x0000001d 0x00000005 0x0000001c 0x0000000b>;
                    reset-names = "arb", "rst";
                    amlogic,fifo-depth = <0x00000100>;
                    status = "okay";
                    phandle = <0x0000004c>;
                };
                reset-controller@280 {
                    status = "okay";
                    compatible = "amlogic,meson-axg-audio-arb";
                    reg = <0x00000000 0x00000280 0x00000000 0x00000004>;
                    #reset-cells = <0x00000001>;
                    clocks = <0x0000001c 0x0000001d>;
                    phandle = <0x0000001d>;
                };
                audio-controller@300 {
                    compatible = "amlogic,g12a-tdmin", "amlogic,axg-tdmin";
                    reg = <0x00000000 0x00000300 0x00000000 0x00000040>;
                    sound-name-prefix = "TDMIN_A";
                    resets = <0x0000001c 0x00000001>;
                    clocks = <0x0000001c 0x0000001f 0x0000001c 0x0000007b 0x0000001c 0x00000074 0x0000001c 0x00000082 0x0000001c 0x00000082>;
                    clock-names = "pclk", "sclk", "sclk_sel", "lrclk", "lrclk_sel";
                    status = "disabled";
                    phandle = <0x000000e5>;
                };
                audio-controller@340 {
                    compatible = "amlogic,g12a-tdmin", "amlogic,axg-tdmin";
                    reg = <0x00000000 0x00000340 0x00000000 0x00000040>;
                    sound-name-prefix = "TDMIN_B";
                    resets = <0x0000001c 0x00000002>;
                    clocks = <0x0000001c 0x00000020 0x0000001c 0x0000007c 0x0000001c 0x00000075 0x0000001c 0x00000083 0x0000001c 0x00000083>;
                    clock-names = "pclk", "sclk", "sclk_sel", "lrclk", "lrclk_sel";
                    status = "disabled";
                    phandle = <0x000000e6>;
                };
                audio-controller@380 {
                    compatible = "amlogic,g12a-tdmin", "amlogic,axg-tdmin";
                    reg = <0x00000000 0x00000380 0x00000000 0x00000040>;
                    sound-name-prefix = "TDMIN_C";
                    resets = <0x0000001c 0x00000003>;
                    clocks = <0x0000001c 0x00000021 0x0000001c 0x0000007d 0x0000001c 0x00000076 0x0000001c 0x00000084 0x0000001c 0x00000084>;
                    clock-names = "pclk", "sclk", "sclk_sel", "lrclk", "lrclk_sel";
                    status = "disabled";
                    phandle = <0x000000e7>;
                };
                audio-controller@3c0 {
                    compatible = "amlogic,g12a-tdmin", "amlogic,axg-tdmin";
                    reg = <0x00000000 0x000003c0 0x00000000 0x00000040>;
                    sound-name-prefix = "TDMIN_LB";
                    resets = <0x0000001c 0x00000004>;
                    clocks = <0x0000001c 0x00000022 0x0000001c 0x0000007e 0x0000001c 0x00000077 0x0000001c 0x00000085 0x0000001c 0x00000085>;
                    clock-names = "pclk", "sclk", "sclk_sel", "lrclk", "lrclk_sel";
                    status = "disabled";
                    phandle = <0x000000e8>;
                };
                audio-controller@400 {
                    compatible = "amlogic,g12a-spdifin", "amlogic,axg-spdifin";
                    reg = <0x00000000 0x00000400 0x00000000 0x00000030>;
                    #sound-dai-cells = <0x00000000>;
                    sound-name-prefix = "SPDIFIN";
                    interrupts = <0x00000000 0x00000097 0x00000001>;
                    clocks = <0x0000001c 0x0000002d 0x0000001c 0x00000038>;
                    clock-names = "pclk", "refclk";
                    resets = <0x0000001c 0x00000011>;
                    status = "disabled";
                    phandle = <0x000000e9>;
                };
                audio-controller@480 {
                    compatible = "amlogic,g12a-spdifout", "amlogic,axg-spdifout";
                    reg = <0x00000000 0x00000480 0x00000000 0x00000050>;
                    #sound-dai-cells = <0x00000000>;
                    sound-name-prefix = "SPDIFOUT";
                    clocks = <0x0000001c 0x0000002e 0x0000001c 0x00000037>;
                    clock-names = "pclk", "mclk";
                    resets = <0x0000001c 0x0000000f>;
                    status = "okay";
                    pinctrl-0 = <0x0000001e>;
                    pinctrl-names = "default";
                    phandle = <0x0000004f>;
                };
                audio-controller@500 {
                    compatible = "amlogic,g12a-tdmout";
                    reg = <0x00000000 0x00000500 0x00000000 0x00000040>;
                    sound-name-prefix = "TDMOUT_A";
                    resets = <0x0000001c 0x0000000c>;
                    clocks = <0x0000001c 0x00000023 0x0000001c 0x0000007f 0x0000001c 0x00000078 0x0000001c 0x00000086 0x0000001c 0x00000086>;
                    clock-names = "pclk", "sclk", "sclk_sel", "lrclk", "lrclk_sel";
                    status = "disabled";
                    phandle = <0x000000ea>;
                };
                audio-controller@540 {
                    compatible = "amlogic,g12a-tdmout";
                    reg = <0x00000000 0x00000540 0x00000000 0x00000040>;
                    sound-name-prefix = "TDMOUT_B";
                    resets = <0x0000001c 0x0000000d>;
                    clocks = <0x0000001c 0x00000024 0x0000001c 0x00000080 0x0000001c 0x00000079 0x0000001c 0x00000087 0x0000001c 0x00000087>;
                    clock-names = "pclk", "sclk", "sclk_sel", "lrclk", "lrclk_sel";
                    status = "okay";
                    phandle = <0x00000049>;
                };
                audio-controller@580 {
                    compatible = "amlogic,g12a-tdmout";
                    reg = <0x00000000 0x00000580 0x00000000 0x00000040>;
                    sound-name-prefix = "TDMOUT_C";
                    resets = <0x0000001c 0x0000000e>;
                    clocks = <0x0000001c 0x00000025 0x0000001c 0x00000081 0x0000001c 0x0000007a 0x0000001c 0x00000088 0x0000001c 0x00000088>;
                    clock-names = "pclk", "sclk", "sclk_sel", "lrclk", "lrclk_sel";
                    status = "disabled";
                    phandle = <0x000000eb>;
                };
                audio-controller@680 {
                    compatible = "amlogic,g12a-spdifout", "amlogic,axg-spdifout";
                    reg = <0x00000000 0x00000680 0x00000000 0x00000050>;
                    #sound-dai-cells = <0x00000000>;
                    sound-name-prefix = "SPDIFOUT_B";
                    clocks = <0x0000001c 0x00000097 0x0000001c 0x00000098>;
                    clock-names = "pclk", "mclk";
                    resets = <0x0000001c 0x00000010>;
                    status = "okay";
                    phandle = <0x00000051>;
                };
                audio-controller@740 {
                    compatible = "amlogic,g12a-toacodec";
                    reg = <0x00000000 0x00000740 0x00000000 0x00000004>;
                    #sound-dai-cells = <0x00000001>;
                    sound-name-prefix = "TOACODEC";
                    resets = <0x0000001c 0x00000017>;
                    status = "disabled";
                    phandle = <0x000000ec>;
                };
                audio-controller@744 {
                    compatible = "amlogic,g12a-tohdmitx";
                    reg = <0x00000000 0x00000744 0x00000000 0x00000004>;
                    #sound-dai-cells = <0x00000001>;
                    sound-name-prefix = "TOHDMITX";
                    resets = <0x0000001c 0x00000018>;
                    status = "okay";
                    phandle = <0x0000004e>;
                };
            };
        };
        bus@ff800000 {
            compatible = "simple-bus";
            reg = <0x00000000 0xff800000 0x00000000 0x00100000>;
            #address-cells = <0x00000002>;
            #size-cells = <0x00000002>;
            ranges = <0x00000000 0x00000000 0x00000000 0xff800000 0x00000000 0x00100000>;
            phandle = <0x000000ed>;
            sys-ctrl@0 {
                compatible = "amlogic,meson-gx-ao-sysctrl", "simple-mfd", "syscon";
                reg = <0x00000000 0x00000000 0x00000000 0x00000100>;
                #address-cells = <0x00000002>;
                #size-cells = <0x00000002>;
                ranges = <0x00000000 0x00000000 0x00000000 0x00000000 0x00000000 0x00000100>;
                phandle = <0x0000001a>;
                clock-controller {
                    compatible = "amlogic,meson-g12a-aoclkc";
                    #clock-cells = <0x00000001>;
                    #reset-cells = <0x00000001>;
                    clocks = <0x00000019 0x00000002 0x0000000a>;
                    clock-names = "xtal", "mpeg-clk";
                    phandle = <0x00000020>;
                };
                pinctrl@14 {
                    compatible = "amlogic,meson-g12a-aobus-pinctrl";
                    #address-cells = <0x00000002>;
                    #size-cells = <0x00000002>;
                    ranges;
                    phandle = <0x0000001f>;
                    bank@14 {
                        reg = <0x00000000 0x00000014 0x00000000 0x00000008 0x00000000 0x0000001c 0x00000000 0x00000008 0x00000000 0x00000024 0x00000000 0x00000014>;
                        reg-names = "mux", "ds", "gpio";
                        gpio-controller;
                        #gpio-cells = <0x00000002>;
                        gpio-ranges = <0x0000001f 0x00000000 0x00000000 0x0000000f>;
                        phandle = <0x00000052>;
                    };
                    i2c_ao_sck_pins {
                        phandle = <0x000000ee>;
                        mux {
                            groups = "i2c_ao_sck";
                            function = "i2c_ao";
                            bias-disable;
                            drive-strength-microamp = <0x00000bb8>;
                        };
                    };
                    i2c_ao_sda {
                        phandle = <0x000000ef>;
                        mux {
                            groups = "i2c_ao_sda";
                            function = "i2c_ao";
                            bias-disable;
                            drive-strength-microamp = <0x00000bb8>;
                        };
                    };
                    i2c_ao_sck_e {
                        phandle = <0x000000f0>;
                        mux {
                            groups = "i2c_ao_sck_e";
                            function = "i2c_ao";
                            bias-disable;
                            drive-strength-microamp = <0x00000bb8>;
                        };
                    };
                    i2c_ao_sda_e {
                        phandle = <0x000000f1>;
                        mux {
                            groups = "i2c_ao_sda_e";
                            function = "i2c_ao";
                            bias-disable;
                            drive-strength-microamp = <0x00000bb8>;
                        };
                    };
                    mclk0-ao {
                        phandle = <0x000000f2>;
                        mux {
                            groups = "mclk0_ao";
                            function = "mclk0_ao";
                            bias-disable;
                            drive-strength-microamp = <0x00000bb8>;
                        };
                    };
                    tdm-ao-b-din0 {
                        phandle = <0x000000f3>;
                        mux {
                            groups = "tdm_ao_b_din0";
                            function = "tdm_ao_b";
                            bias-disable;
                        };
                    };
                    spdif-ao-out {
                        phandle = <0x000000f4>;
                        mux {
                            groups = "spdif_ao_out";
                            function = "spdif_ao_out";
                            drive-strength-microamp = <0x000001f4>;
                            bias-disable;
                        };
                    };
                    tdm-ao-b-din1 {
                        phandle = <0x000000f5>;
                        mux {
                            groups = "tdm_ao_b_din1";
                            function = "tdm_ao_b";
                            bias-disable;
                        };
                    };
                    tdm-ao-b-din2 {
                        phandle = <0x000000f6>;
                        mux {
                            groups = "tdm_ao_b_din2";
                            function = "tdm_ao_b";
                            bias-disable;
                        };
                    };
                    tdm-ao-b-dout0 {
                        phandle = <0x000000f7>;
                        mux {
                            groups = "tdm_ao_b_dout0";
                            function = "tdm_ao_b";
                            bias-disable;
                            drive-strength-microamp = <0x00000bb8>;
                        };
                    };
                    tdm-ao-b-dout1 {
                        phandle = <0x000000f8>;
                        mux {
                            groups = "tdm_ao_b_dout1";
                            function = "tdm_ao_b";
                            bias-disable;
                            drive-strength-microamp = <0x00000bb8>;
                        };
                    };
                    tdm-ao-b-dout2 {
                        phandle = <0x000000f9>;
                        mux {
                            groups = "tdm_ao_b_dout2";
                            function = "tdm_ao_b";
                            bias-disable;
                            drive-strength-microamp = <0x00000bb8>;
                        };
                    };
                    tdm-ao-b-fs {
                        phandle = <0x000000fa>;
                        mux {
                            groups = "tdm_ao_b_fs";
                            function = "tdm_ao_b";
                            bias-disable;
                            drive-strength-microamp = <0x00000bb8>;
                        };
                    };
                    tdm-ao-b-sclk {
                        phandle = <0x000000fb>;
                        mux {
                            groups = "tdm_ao_b_sclk";
                            function = "tdm_ao_b";
                            bias-disable;
                            drive-strength-microamp = <0x00000bb8>;
                        };
                    };
                    tdm-ao-b-slv-fs {
                        phandle = <0x000000fc>;
                        mux {
                            groups = "tdm_ao_b_slv_fs";
                            function = "tdm_ao_b";
                            bias-disable;
                        };
                    };
                    tdm-ao-b-slv-sclk {
                        phandle = <0x000000fd>;
                        mux {
                            groups = "tdm_ao_b_slv_sclk";
                            function = "tdm_ao_b";
                            bias-disable;
                        };
                    };
                    uart-a-ao {
                        phandle = <0x00000025>;
                        mux {
                            groups = "uart_ao_a_tx", "uart_ao_a_rx";
                            function = "uart_ao_a";
                            bias-pull-up;
                        };
                    };
                    uart-ao-a-cts-rts {
                        phandle = <0x000000fe>;
                        mux {
                            groups = "uart_ao_a_cts", "uart_ao_a_rts";
                            function = "uart_ao_a";
                            bias-pull-up;
                        };
                    };
                    pwm-a-e {
                        phandle = <0x000000ff>;
                        mux {
                            groups = "pwm_a_e";
                            function = "pwm_a_e";
                            bias-disable;
                        };
                    };
                    pwm-ao-a {
                        phandle = <0x00000100>;
                        mux {
                            groups = "pwm_ao_a";
                            function = "pwm_ao_a";
                            bias-disable;
                        };
                    };
                    pwm-ao-b {
                        phandle = <0x00000101>;
                        mux {
                            groups = "pwm_ao_b";
                            function = "pwm_ao_b";
                            bias-disable;
                        };
                    };
                    pwm-ao-c-4 {
                        phandle = <0x00000102>;
                        mux {
                            groups = "pwm_ao_c_4";
                            function = "pwm_ao_c";
                            bias-disable;
                        };
                    };
                    pwm-ao-c-6 {
                        phandle = <0x00000103>;
                        mux {
                            groups = "pwm_ao_c_6";
                            function = "pwm_ao_c";
                            bias-disable;
                        };
                    };
                    pwm-ao-d-5 {
                        phandle = <0x00000104>;
                        mux {
                            groups = "pwm_ao_d_5";
                            function = "pwm_ao_d";
                            bias-disable;
                        };
                    };
                    pwm-ao-d-10 {
                        phandle = <0x00000105>;
                        mux {
                            groups = "pwm_ao_d_10";
                            function = "pwm_ao_d";
                            bias-disable;
                        };
                    };
                    pwm-ao-d-e {
                        phandle = <0x00000024>;
                        mux {
                            groups = "pwm_ao_d_e";
                            function = "pwm_ao_d";
                        };
                    };
                    remote-input-ao {
                        phandle = <0x00000026>;
                        mux {
                            groups = "remote_ao_input";
                            function = "remote_ao_input";
                            bias-disable;
                        };
                    };
                };
            };
            rtc@a8 {
                compatible = "amlogic,meson-vrtc";
                reg = <0x00000000 0x000000a8 0x00000000 0x00000004>;
                phandle = <0x00000106>;
            };
            cec@100 {
                compatible = "amlogic,meson-gx-ao-cec";
                reg = <0x00000000 0x00000100 0x00000000 0x00000014>;
                interrupts = <0x00000000 0x000000c7 0x00000001>;
                clocks = <0x00000020 0x0000001b>;
                clock-names = "core";
                status = "disabled";
                pinctrl-0 = <0x00000021>;
                pinctrl-names = "default";
                hdmi-phandle = <0x00000022>;
                phandle = <0x00000107>;
            };
            ao-secure@140 {
                compatible = "amlogic,meson-gx-ao-secure", "syscon";
                reg = <0x00000000 0x00000140 0x00000000 0x00000140>;
                amlogic,has-chip-id;
                phandle = <0x00000018>;
            };
            cec@280 {
                compatible = "amlogic,meson-g12a-ao-cec";
                reg = <0x00000000 0x00000280 0x00000000 0x0000001c>;
                interrupts = <0x00000000 0x000000cb 0x00000001>;
                clocks = <0x00000020 0x00000013>;
                clock-names = "oscin";
                status = "okay";
                pinctrl-0 = <0x00000023>;
                pinctrl-names = "default";
                hdmi-phandle = <0x00000022>;
                phandle = <0x00000108>;
            };
            pwm@2000 {
                compatible = "amlogic,meson-g12a-ao-pwm-cd";
                reg = <0x00000000 0x00002000 0x00000000 0x00000020>;
                #pwm-cells = <0x00000003>;
                status = "okay";
                pinctrl-0 = <0x00000024>;
                pinctrl-names = "default";
                clocks = <0x00000019>;
                clock-names = "clkin1";
                phandle = <0x00000048>;
            };
            serial@3000 {
                compatible = "amlogic,meson-gx-uart", "amlogic,meson-ao-uart";
                reg = <0x00000000 0x00003000 0x00000000 0x00000018>;
                interrupts = <0x00000000 0x000000c1 0x00000001>;
                clocks = <0x00000019 0x00000020 0x00000004 0x00000019>;
                clock-names = "xtal", "pclk", "baud";
                status = "okay";
                pinctrl-0 = <0x00000025>;
                pinctrl-names = "default";
                phandle = <0x00000109>;
            };
            serial@4000 {
                compatible = "amlogic,meson-gx-uart", "amlogic,meson-ao-uart";
                reg = <0x00000000 0x00004000 0x00000000 0x00000018>;
                interrupts = <0x00000000 0x000000c5 0x00000001>;
                clocks = <0x00000019 0x00000020 0x00000006 0x00000019>;
                clock-names = "xtal", "pclk", "baud";
                status = "disabled";
                phandle = <0x0000010a>;
            };
            i2c@5000 {
                compatible = "amlogic,meson-axg-i2c";
                status = "disabled";
                reg = <0x00000000 0x00005000 0x00000000 0x00000020>;
                interrupts = <0x00000000 0x000000c3 0x00000001>;
                #address-cells = <0x00000001>;
                #size-cells = <0x00000000>;
                clocks = <0x00000002 0x00000018>;
                phandle = <0x0000010b>;
            };
            pwm@7000 {
                compatible = "amlogic,meson-g12a-ao-pwm-ab";
                reg = <0x00000000 0x00007000 0x00000000 0x00000020>;
                #pwm-cells = <0x00000003>;
                status = "disabled";
                phandle = <0x0000010c>;
            };
            ir@8000 {
                compatible = "amlogic,meson-gxbb-ir";
                reg = <0x00000000 0x00008000 0x00000000 0x00000020>;
                interrupts = <0x00000000 0x000000c4 0x00000001>;
                status = "okay";
                pinctrl-0 = <0x00000026>;
                pinctrl-names = "default";
                phandle = <0x0000010d>;
            };
            adc@9000 {
                compatible = "amlogic,meson-g12a-saradc", "amlogic,meson-saradc";
                reg = <0x00000000 0x00009000 0x00000000 0x00000048>;
                #io-channel-cells = <0x00000001>;
                interrupts = <0x00000000 0x000000c8 0x00000001>;
                clocks = <0x00000019 0x00000020 0x00000008 0x00000020 0x00000012 0x00000020 0x00000010>;
                clock-names = "clkin", "core", "adc_clk", "adc_sel";
                status = "disabled";
                phandle = <0x0000010e>;
            };
        };
        video-decoder@ff620000 {
            compatible = "amlogic,g12a-vdec";
            reg = <0x00000000 0xff620000 0x00000000 0x00010000 0x00000000 0xffd0e180 0x00000000 0x000000e4>;
            reg-names = "dos", "esparser";
            interrupts = <0x00000000 0x0000002c 0x00000001 0x00000000 0x00000020 0x00000001>;
            interrupt-names = "vdec", "esparser";
            amlogic,ao-sysctrl = <0x0000001a>;
            amlogic,canvas = <0x00000027>;
            clocks = <0x00000002 0x0000002e 0x00000002 0x00000010 0x00000002 0x000000cc 0x00000002 0x000000cf 0x00000002 0x000000d2>;
            clock-names = "dos_parser", "dos", "vdec_1", "vdec_hevc", "vdec_hevcf";
            resets = <0x00000005 0x00000028>;
            reset-names = "esparser";
            phandle = <0x0000010f>;
        };
        vpu@ff900000 {
            compatible = "amlogic,meson-g12a-vpu";
            reg = <0x00000000 0xff900000 0x00000000 0x00100000 0x00000000 0xff63c000 0x00000000 0x00001000>;
            reg-names = "vpu", "hhi";
            interrupts = <0x00000000 0x00000003 0x00000001>;
            #address-cells = <0x00000001>;
            #size-cells = <0x00000000>;
            amlogic,canvas = <0x00000027>;
            power-domains = <0x00000003 0x00000000>;
            phandle = <0x00000110>;
            port@0 {
                reg = <0x00000000>;
                phandle = <0x00000111>;
                endpoint {
                    remote-endpoint = <0x00000028>;
                    phandle = <0x00000045>;
                };
            };
            port@1 {
                reg = <0x00000001>;
                phandle = <0x00000112>;
                endpoint {
                    remote-endpoint = <0x00000029>;
                    phandle = <0x00000015>;
                };
            };
        };
        interrupt-controller@ffc01000 {
            compatible = "arm,gic-400";
            reg = <0x00000000 0xffc01000 0x00000000 0x00001000 0x00000000 0xffc02000 0x00000000 0x00002000 0x00000000 0xffc04000 0x00000000 0x00002000 0x00000000 0xffc06000 0x00000000 0x00002000>;
            interrupt-controller;
            interrupts = <0x00000001 0x00000009 0x0000ff04>;
            #interrupt-cells = <0x00000003>;
            #address-cells = <0x00000000>;
            phandle = <0x00000001>;
        };
        bus@ffd00000 {
            compatible = "simple-bus";
            reg = <0x00000000 0xffd00000 0x00000000 0x00100000>;
            #address-cells = <0x00000002>;
            #size-cells = <0x00000002>;
            ranges = <0x00000000 0x00000000 0x00000000 0xffd00000 0x00000000 0x00100000>;
            phandle = <0x00000113>;
            reset-controller@1004 {
                compatible = "amlogic,meson-axg-reset";
                reg = <0x00000000 0x00001004 0x00000000 0x0000009c>;
                #reset-cells = <0x00000001>;
                phandle = <0x00000005>;
            };
            interrupt-controller@f080 {
                compatible = "amlogic,meson-g12a-gpio-intc", "amlogic,meson-gpio-intc";
                reg = <0x00000000 0x0000f080 0x00000000 0x00000010>;
                interrupt-controller;
                #interrupt-cells = <0x00000002>;
                amlogic,channel-interrupts = <0x00000040 0x00000041 0x00000042 0x00000043 0x00000044 0x00000045 0x00000046 0x00000047>;
                phandle = <0x00000114>;
            };
            watchdog@f0d0 {
                compatible = "amlogic,meson-gxbb-wdt";
                reg = <0x00000000 0x0000f0d0 0x00000000 0x00000010>;
                clocks = <0x00000019>;
                phandle = <0x00000115>;
            };
            spi@13000 {
                compatible = "amlogic,meson-g12a-spicc";
                reg = <0x00000000 0x00013000 0x00000000 0x00000044>;
                interrupts = <0x00000000 0x00000051 0x00000004>;
                clocks = <0x00000002 0x00000017 0x00000002 0x00000102>;
                clock-names = "core", "pclk";
                #address-cells = <0x00000001>;
                #size-cells = <0x00000000>;
                status = "disabled";
                phandle = <0x00000116>;
            };
            spi@15000 {
                compatible = "amlogic,meson-g12a-spicc";
                reg = <0x00000000 0x00015000 0x00000000 0x00000044>;
                interrupts = <0x00000000 0x0000005a 0x00000004>;
                clocks = <0x00000002 0x0000001d 0x00000002 0x00000105>;
                clock-names = "core", "pclk";
                #address-cells = <0x00000001>;
                #size-cells = <0x00000000>;
                status = "disabled";
                phandle = <0x00000117>;
            };
            spi@14000 {
                compatible = "amlogic,meson-gxbb-spifc";
                status = "disabled";
                reg = <0x00000000 0x00014000 0x00000000 0x00000080>;
                #address-cells = <0x00000001>;
                #size-cells = <0x00000000>;
                clocks = <0x00000002 0x0000000a>;
                phandle = <0x00000118>;
            };
            pwm@19000 {
                compatible = "amlogic,meson-g12a-ee-pwm";
                reg = <0x00000000 0x00019000 0x00000000 0x00000020>;
                #pwm-cells = <0x00000003>;
                phandle = <0x00000119>;
                status = "okay";
            };
            pwm@1a000 {
                compatible = "amlogic,meson-g12a-ee-pwm";
                reg = <0x00000000 0x0001a000 0x00000000 0x00000020>;
                #pwm-cells = <0x00000003>;
                status = "disabled";
                phandle = <0x0000011a>;
            };
            pwm@1b000 {
                compatible = "amlogic,meson-g12a-ee-pwm";
                reg = <0x00000000 0x0001b000 0x00000000 0x00000020>;
                #pwm-cells = <0x00000003>;
                status = "disabled";
                phandle = <0x0000011b>;
            };
            i2c@1c000 {
                compatible = "amlogic,meson-axg-i2c";
                status = "okay";
                reg = <0x00000000 0x0001c000 0x00000000 0x00000020>;
                interrupts = <0x00000000 0x00000027 0x00000001>;
                #address-cells = <0x00000001>;
                #size-cells = <0x00000000>;
                clocks = <0x00000002 0x00000018>;
                pinctrl-0 = <0x0000002a 0x0000002b>;
                pinctrl-names = "default";
                phandle = <0x0000011c>;
            };
            i2c@1d000 {
                compatible = "amlogic,meson-axg-i2c";
                status = "okay";
                reg = <0x00000000 0x0001d000 0x00000000 0x00000020>;
                interrupts = <0x00000000 0x000000d7 0x00000001>;
                #address-cells = <0x00000001>;
                #size-cells = <0x00000000>;
                clocks = <0x00000002 0x00000018>;
                pinctrl-0 = <0x0000002c 0x0000002d>;
                pinctrl-names = "default";
                phandle = <0x0000011d>;
            };
            i2c@1e000 {
                compatible = "amlogic,meson-axg-i2c";
                status = "disabled";
                reg = <0x00000000 0x0001e000 0x00000000 0x00000020>;
                interrupts = <0x00000000 0x000000d6 0x00000001>;
                #address-cells = <0x00000001>;
                #size-cells = <0x00000000>;
                clocks = <0x00000002 0x00000018>;
                phandle = <0x0000011e>;
            };
            i2c@1f000 {
                compatible = "amlogic,meson-axg-i2c";
                status = "okay";
                reg = <0x00000000 0x0001f000 0x00000000 0x00000020>;
                interrupts = <0x00000000 0x00000015 0x00000001>;
                #address-cells = <0x00000001>;
                #size-cells = <0x00000000>;
                clocks = <0x00000002 0x00000018>;
                pinctrl-0 = <0x0000002e 0x0000002f>;
                pinctrl-names = "default";
                phandle = <0x0000011f>;
            };
            clock-measure@18000 {
                compatible = "amlogic,meson-g12a-clk-measure";
                reg = <0x00000000 0x00018000 0x00000000 0x00000010>;
                phandle = <0x00000120>;
            };
            serial@22000 {
                compatible = "amlogic,meson-gx-uart";
                reg = <0x00000000 0x00022000 0x00000000 0x00000018>;
                interrupts = <0x00000000 0x0000005d 0x00000001>;
                clocks = <0x00000019 0x00000002 0x00000039 0x00000019>;
                clock-names = "xtal", "pclk", "baud";
                status = "disabled";
                phandle = <0x00000121>;
            };
            serial@23000 {
                compatible = "amlogic,meson-gx-uart";
                reg = <0x00000000 0x00023000 0x00000000 0x00000018>;
                interrupts = <0x00000000 0x0000004b 0x00000001>;
                clocks = <0x00000019 0x00000002 0x0000002a 0x00000019>;
                clock-names = "xtal", "pclk", "baud";
                status = "disabled";
                phandle = <0x00000122>;
            };
            serial@24000 {
                compatible = "amlogic,meson-gx-uart";
                reg = <0x00000000 0x00024000 0x00000000 0x00000018>;
                interrupts = <0x00000000 0x0000001a 0x00000001>;
                clocks = <0x00000019 0x00000002 0x0000001c 0x00000019>;
                clock-names = "xtal", "pclk", "baud";
                status = "okay";
                fifo-size = <0x00000080>;
                pinctrl-0 = <0x00000030 0x00000031>;
                uart-has-rtscts;
                pinctrl-names = "default";
                phandle = <0x00000123>;
            };
        };
        sd@ffe03000 {
            compatible = "amlogic,meson-axg-mmc";
            reg = <0x00000000 0xffe03000 0x00000000 0x00000800>;
            interrupts = <0x00000000 0x000000bd 0x00000004>;
            clocks = <0x00000002 0x00000021 0x00000002 0x0000003c 0x00000002 0x00000002>;
            clock-names = "core", "clkin0", "clkin1";
            resets = <0x00000005 0x0000002c>;
            amlogic,dram-access-quirk;
            phandle = <0x00000124>;
            status = "okay";
            bus-width = <0x00000004>;
            max-frequency = <0x017d7840>;
            mmc-pwrseq = <0x00002002>;
            vmmc-supply = <0x00000035>;
            vqmmc-supply = <0x0000012d>;
            cap-sdio-irq;
            non-removable;
            keep-power-in-suspend;
            wifi@1 {
                compatible = "uwcnmodem,we5621ds";
                reg = <0x00000001>;
                status = "okay";
            };
        };
        sd@ffe05000 {
            compatible = "amlogic,meson-axg-mmc";
            reg = <0x00000000 0xffe05000 0x00000000 0x00000800>;
            interrupts = <0x00000000 0x000000be 0x00000004>;
            clocks = <0x00000002 0x00000022 0x00000002 0x0000003d 0x00000002 0x00000002>;
            clock-names = "core", "clkin0", "clkin1";
            resets = <0x00000005 0x0000002d>;
            cap-sd-highspeed;
            disable-wp;
            phandle = <0x00000125>;
            pinctrl-0 = <0x0000009a>;
            pinctrl-1 = <0x0000009b>;
            pinctrl-names = "default", "clk-gate";
            bus-width = <0x00000004>;
            max-frequency = <0x017d7840>;
            vmmc-supply = <0x00000035>;
            vqmmc-supply = <0x0000012d>;
            cap-sdio-irq;
            non-removable;
            keep-power-in-suspend;
            status = "disabled";
            sdio {
                pinname = "sdio";
                ocr_avail = <0x00200080>;
                max_req_size = <0x00020000>;
                card_type = <0x00000003>;
                caps = "MMC_CAP_4_BIT_DATA", "MMC_CAP_MMC_HIGHSPEED", "MMC_CAP_SD_HIGHSPEED", "MMC_CAP_NONREMOVABLE", "MMC_PM_KEEP_POWER", "MMC_CAP_SDIO_IRQ";
                f_min = <0x00061a80>;
                f_max = <0x017d7840>;
            };
        };
        mmc@ffe07000 {
            compatible = "amlogic,meson-axg-mmc";
            reg = <0x00000000 0xffe07000 0x00000000 0x00000800>;
            interrupts = <0x00000000 0x000000bf 0x00000004>;
            status = "okay";
            clocks = <0x00000002 0x00000023 0x00000002 0x0000003e 0x00000002 0x00000002>;
            clock-names = "core", "clkin0", "clkin1";
            resets = <0x00000005 0x0000002e>;
            pinctrl-0 = <0x00000036 0x00000037 0x00000038>;
            pinctrl-1 = <0x00000039>;
            pinctrl-names = "default", "clk-gate";
            bus-width = <0x00000008>;
            cap-mmc-highspeed;
            mmc-ddr-1_8v;
            mmc-hs200-1_8v;
            max-frequency = <0x05f5e100>;
            non-removable;
            disable-wp;
            mmc-pwrseq = <0x0000003a>;
            vmmc-supply = <0x0000003b>;
            vqmmc-supply = <0x0000003c>;
            phandle = <0x00000126>;
        };
        usb@ffe09000 {
            status = "okay";
            compatible = "amlogic,meson-g12a-usb-ctrl";
            reg = <0x00000000 0xffe09000 0x00000000 0x000000a0>;
            interrupts = <0x00000000 0x00000010 0x00000004>;
            #address-cells = <0x00000002>;
            #size-cells = <0x00000002>;
            ranges;
            clocks = <0x00000002 0x0000002f>;
            resets = <0x00000005 0x00000022>;
            dr_mode = "otg";
            phys = <0x0000003d 0x0000003e 0x00000006 0x00000004>;
            phy-names = "usb2-phy0", "usb2-phy1", "usb3-phy0";
            vbus-supply = <0x0000003f>;
            phandle = <0x00000127>;
            usb@ff400000 {
                compatible = "amlogic,meson-g12a-usb", "snps,dwc2";
                reg = <0x00000000 0xff400000 0x00000000 0x00040000>;
                interrupts = <0x00000000 0x0000001f 0x00000004>;
                clocks = <0x00000002 0x00000037>;
                clock-names = "otg";
                phys = <0x0000003e>;
                phy-names = "usb2-phy";
                dr_mode = "peripheral";
                g-rx-fifo-size = <0x000000c0>;
                g-np-tx-fifo-size = <0x00000080>;
                g-tx-fifo-size = <0x00000080 0x00000080 0x00000010 0x00000010 0x00000010>;
                phandle = <0x00000128>;
            };
            usb@ff500000 {
                compatible = "snps,dwc3";
                reg = <0x00000000 0xff500000 0x00000000 0x00100000>;
                interrupts = <0x00000000 0x0000001e 0x00000004>;
                dr_mode = "host";
                snps,dis_u2_susphy_quirk;
                snps,quirk-frame-length-adjustment = <0x00000020>;
                snps,parkmode-disable-ss-quirk;
                phandle = <0x00000129>;
            };
        };
        gpu@ffe40000 {
            compatible = "amlogic,meson-g12a-mali", "arm,mali-bifrost";
            reg = <0x00000000 0xffe40000 0x00000000 0x00040000>;
            interrupt-parent = <0x00000001>;
            interrupts = <0x00000000 0x000000a2 0x00000004 0x00000000 0x000000a1 0x00000004 0x00000000 0x000000a0 0x00000004>;
            interrupt-names = "job", "mmu", "gpu";
            clocks = <0x00000002 0x000000af>;
            resets = <0x00000005 0x00000014 0x00000005 0x0000004e>;
            operating-points-v2 = <0x00000040>;
            #cooling-cells = <0x00000002>;
            mali-supply = <0x00000041>;
            phandle = <0x00000010>;
        };
    };
    timer {
        compatible = "arm,armv8-timer";
        interrupts = <0x00000001 0x0000000d 0x0000ff08 0x00000001 0x0000000e 0x0000ff08 0x00000001 0x0000000b 0x0000ff08 0x00000001 0x0000000a 0x0000ff08>;
        arm,no-tick-in-suspend;
    };
    xtal-clk {
        compatible = "fixed-clock";
        clock-frequency = <0x016e3600>;
        clock-output-names = "xtal";
        #clock-cells = <0x00000000>;
        phandle = <0x00000019>;
    };
    audio-controller-0 {
        compatible = "amlogic,axg-tdm-iface";
        #sound-dai-cells = <0x00000000>;
        sound-name-prefix = "TDM_A";
        clocks = <0x0000001c 0x00000031 0x0000001c 0x0000004f 0x0000001c 0x00000056>;
        clock-names = "mclk", "sclk", "lrclk";
        status = "disabled";
        phandle = <0x0000012a>;
    };
    audio-controller-1 {
        compatible = "amlogic,axg-tdm-iface";
        #sound-dai-cells = <0x00000000>;
        sound-name-prefix = "TDM_B";
        clocks = <0x0000001c 0x00000032 0x0000001c 0x00000050 0x0000001c 0x00000057>;
        clock-names = "mclk", "sclk", "lrclk";
        status = "okay";
        phandle = <0x0000004d>;
    };
    audio-controller-2 {
        compatible = "amlogic,axg-tdm-iface";
        #sound-dai-cells = <0x00000000>;
        sound-name-prefix = "TDM_C";
        clocks = <0x0000001c 0x00000033 0x0000001c 0x00000051 0x0000001c 0x00000058>;
        clock-names = "mclk", "sclk", "lrclk";
        status = "disabled";
        phandle = <0x0000012b>;
    };
    cpus {
        #address-cells = <0x00000002>;
        #size-cells = <0x00000000>;
        cpu@0 {
            device_type = "cpu";
            compatible = "arm,cortex-a53";
            reg = <0x00000000 0x00000000>;
            enable-method = "psci";
            next-level-cache = <0x00000042>;
            #cooling-cells = <0x00000002>;
            cpu-supply = <0x00000043>;
            operating-points-v2 = <0x00000044>;
            clocks = <0x00000002 0x000000bb>;
            clock-latency = <0x0000c350>;
            phandle = <0x00000009>;
        };
        cpu@1 {
            device_type = "cpu";
            compatible = "arm,cortex-a53";
            reg = <0x00000000 0x00000001>;
            enable-method = "psci";
            next-level-cache = <0x00000042>;
            #cooling-cells = <0x00000002>;
            cpu-supply = <0x00000043>;
            operating-points-v2 = <0x00000044>;
            clocks = <0x00000002 0x000000bb>;
            clock-latency = <0x0000c350>;
            phandle = <0x0000000a>;
        };
        cpu@2 {
            device_type = "cpu";
            compatible = "arm,cortex-a53";
            reg = <0x00000000 0x00000002>;
            enable-method = "psci";
            next-level-cache = <0x00000042>;
            #cooling-cells = <0x00000002>;
            cpu-supply = <0x00000043>;
            operating-points-v2 = <0x00000044>;
            clocks = <0x00000002 0x000000bb>;
            clock-latency = <0x0000c350>;
            phandle = <0x0000000b>;
        };
        cpu@3 {
            device_type = "cpu";
            compatible = "arm,cortex-a53";
            reg = <0x00000000 0x00000003>;
            enable-method = "psci";
            next-level-cache = <0x00000042>;
            #cooling-cells = <0x00000002>;
            cpu-supply = <0x00000043>;
            operating-points-v2 = <0x00000044>;
            clocks = <0x00000002 0x000000bb>;
            clock-latency = <0x0000c350>;
            phandle = <0x0000000c>;
        };
        l2-cache0 {
            compatible = "cache";
            phandle = <0x00000042>;
        };
    };
    opp-table {
        compatible = "operating-points-v2";
        opp-shared;
        phandle = <0x00000044>;
        opp-1000000000 {
            opp-hz = <0x00000000 0x3b9aca00>;
            opp-microvolt = <0x000b2778>;
        };
        opp-1200000000 {
            opp-hz = <0x00000000 0x47868c00>;
            opp-microvolt = <0x000b9ca8>;
        };
        opp-1398000000 {
            opp-hz = <0x00000000 0x5353c980>;
            opp-microvolt = <0x000c11d8>;
        };
        opp-1512000000 {
            opp-hz = <0x00000000 0x5a1f4a00>;
            opp-microvolt = <0x000cae18>;
        };
        opp-1608000000 {
            opp-hz = <0x00000000 0x5fd82200>;
            opp-microvolt = <0x000d4a58>;
        };
        opp-1704000000 {
            opp-hz = <0x00000000 0x6590fa00>;
            opp-microvolt = <0x000e0da8>;
        };
        opp-1800000000 {
            opp-hz = <0x00000000 0x6b49d200>;
            opp-microvolt = <0x000ef808>;
            status = "disabled";
        };
        opp-100000000 {
            opp-hz = <0x00000000 0x05f5e100>;
            opp-microvolt = <0x000b2778>;
        };
        opp-250000000 {
            opp-hz = <0x00000000 0x0ee6b280>;
            opp-microvolt = <0x000b2778>;
        };
        opp-500000000 {
            opp-hz = <0x00000000 0x1dcd6500>;
            opp-microvolt = <0x000b2778>;
        };
        opp-667000000 {
            opp-hz = <0x00000000 0x27c19cc0>;
            opp-microvolt = <0x000b2778>;
        };
    };
    audio-codec-1 {
        #sound-dai-cells = <0x00000000>;
        compatible = "linux,spdif-dit";
        status = "okay";
        sound-name-prefix = "DIT";
        phandle = <0x00000050>;
    };
    cvbs-connector {
        compatible = "composite-video-connector";
        port {
            endpoint {
                remote-endpoint = <0x00000045>;
                phandle = <0x00000028>;
            };
        };
    };
    emmc-pwrseq {
        compatible = "mmc-pwrseq-emmc";
        reset-gpios = <0x00000034 0x00000025 0x00000001>;
        phandle = <0x0000003a>;
    };
    hdmi-connector {
        compatible = "hdmi-connector";
        type = "a";
        port {
            endpoint {
                remote-endpoint = <0x00000046>;
                phandle = <0x00000016>;
            };
        };
    };
    memory@0 {
        device_type = "memory";
        reg = <0x00000000 0x00000000 0x00000000 0x80000000>;
    };
    regulator-flash_1v8 {
        compatible = "regulator-fixed";
        regulator-name = "FLASH_1V8";
        regulator-min-microvolt = <0x001b7740>;
        regulator-max-microvolt = <0x001b7740>;
        vin-supply = <0x0000003b>;
        regulator-always-on;
        phandle = <0x0000003c>;
    };
    regulator-main_12v {
        compatible = "regulator-fixed";
        regulator-name = "12V";
        regulator-min-microvolt = <0x00b71b00>;
        regulator-max-microvolt = <0x00b71b00>;
        regulator-always-on;
        phandle = <0x00000047>;
    };
    regulator-usb_pwr_en {
        compatible = "regulator-fixed";
        regulator-name = "USB_PWR_EN";
        regulator-min-microvolt = <0x004c4b40>;
        regulator-max-microvolt = <0x004c4b40>;
        vin-supply = <0x00000014>;
        gpio = <0x00000034 0x00000016 0x00000000>;
        enable-active-high;
        phandle = <0x0000003f>;
    };
    regulator-vcc_1v8 {
        compatible = "regulator-fixed";
        regulator-name = "VCC_1V8";
        regulator-min-microvolt = <0x001b7740>;
        regulator-max-microvolt = <0x001b7740>;
        vin-supply = <0x0000003b>;
        regulator-always-on;
        phandle = <0x0000012c>;
    };
    regulator-vcc_3v3 {
        compatible = "regulator-fixed";
        regulator-name = "VCC_3V3";
        regulator-min-microvolt = <0x00325aa0>;
        regulator-max-microvolt = <0x00325aa0>;
        vin-supply = <0x00000035>;
        regulator-always-on;
        phandle = <0x0000003b>;
    };
    regulator-vcc_5v {
        compatible = "regulator-fixed";
        regulator-name = "VCC_5V";
        regulator-min-microvolt = <0x004c4b40>;
        regulator-max-microvolt = <0x004c4b40>;
        vin-supply = <0x00000047>;
        gpio = <0x00000034 0x00000018 0x00000006>;
        enable-active-high;
        phandle = <0x00000014>;
    };
    regulator-vddao_1v8 {
        compatible = "regulator-fixed";
        regulator-name = "VDDAO_1V8";
        regulator-min-microvolt = <0x001b7740>;
        regulator-max-microvolt = <0x001b7740>;
        vin-supply = <0x00000035>;
        regulator-always-on;
        phandle = <0x0000012d>;
    };
    regulator-vddao_3v3 {
        compatible = "regulator-fixed";
        regulator-name = "VDDAO_3V3";
        regulator-min-microvolt = <0x00325aa0>;
        regulator-max-microvolt = <0x00325aa0>;
        vin-supply = <0x00000047>;
        regulator-always-on;
        phandle = <0x00000035>;
    };
    regulator-vddcpu {
        compatible = "pwm-regulator";
        regulator-name = "VDDCPU";
        regulator-min-microvolt = <0x000b0068>;
        regulator-max-microvolt = <0x000f9830>;
        pwm-supply = <0x00000047>;
        pwms = <0x00000048 0x00000001 0x000004e2 0x00000000>;
        pwm-dutycycle-range = <0x00000064 0x00000000>;
        regulator-boot-on;
        regulator-always-on;
        phandle = <0x00000043>;
    };
    sound {
        compatible = "amlogic,axg-sound-card";
        model = "U200";
        audio-aux-devs = <0x00000049>;
        audio-routing = "TDMOUT_B IN 0", "FRDDR_A OUT 1", "TDMOUT_B IN 1", "FRDDR_B OUT 1", "TDMOUT_B IN 2", "FRDDR_C OUT 1", "TDM_B Playback", "TDMOUT_B OUT", "SPDIFOUT IN 0", "FRDDR_A OUT 3", "SPDIFOUT IN 1", "FRDDR_B OUT 3", "SPDIFOUT IN 2", "FRDDR_C OUT 3";
        assigned-clocks = <0x00000002 0x0000000d 0x00000002 0x0000000b 0x00000002 0x0000000c>;
        assigned-clock-parents = <0x00000000 0x00000000 0x00000000>;
        assigned-clock-rates = <0x11940000 0x10266000 0x17700000>;
        status = "okay";
        dai-link-0 {
            sound-dai = <0x0000004a>;
        };
        dai-link-1 {
            sound-dai = <0x0000004b>;
        };
        dai-link-2 {
            sound-dai = <0x0000004c>;
        };
        dai-link-3 {
            sound-dai = <0x0000004d>;
            dai-format = "i2s";
            dai-tdm-slot-tx-mask-0 = <0x00000001 0x00000001>;
            dai-tdm-slot-tx-mask-1 = <0x00000001 0x00000001>;
            dai-tdm-slot-tx-mask-2 = <0x00000001 0x00000001>;
            dai-tdm-slot-tx-mask-3 = <0x00000001 0x00000001>;
            mclk-fs = <0x00000100>;
            codec {
                sound-dai = <0x0000004e 0x00000001>;
            };
        };
        dai-link-4 {
            sound-dai = <0x0000004f>;
            codec-0 {
                sound-dai = <0x00000050>;
            };
            codec-1 {
                sound-dai = <0x0000004e 0x00000004>;
            };
        };
        dai-link-5 {
            sound-dai = <0x00000051>;
            codec {
                sound-dai = <0x0000004e 0x00000005>;
            };
        };
        dai-link-6 {
            sound-dai = <0x0000004e 0x00000003>;
            codec {
                sound-dai = <0x00000022>;
            };
        };
    };
    regulator-vddgpu {
        compatible = "regulator-fixed";
        regulator-name = "mali";
        regulator-min-microvolt = <0x000c3500>;
        regulator-max-microvolt = <0x000c3500>;
        vin-supply = <0x00000047>;
        regulator-boot-on;
        regulator-always-on;
        phandle = <0x00000041>;
    };
    leds {
        compatible = "gpio-leds";
        power_led {
            led_name = "power_led";
            gpios = <0x00000052 0x0000000b 0x00000001>;
            default-state = "on";
        };
        net_led {
            led_name = "net_led";
            gpios = <0x00000052 0x00000009 0x00000001>;
            default-state = "off";
            linux,default-trigger = "0.0:00:link";
        };
        remote_led {
            led_name = "remote_led";
            gpios = <0x00000052 0x0000000a 0x00000001>;
            default-state = "off";
            linux,default-trigger = "rc-feedback";
        };
    };
    __symbols__ {
        simplefb_cvbs = "/chosen/framebuffer-cvbs";
        simplefb_hdmi = "/chosen/framebuffer-hdmi";
        efuse = "/efuse";
        gpu_opp_table = "/opp-table-gpu";
        secmon_reserved = "/reserved-memory/secmon@5000000";
        secmon_reserved_bl32 = "/reserved-memory/secmon@5300000";
        sm = "/secure-monitor";
        pcie = "/soc/pcie@fc000000";
        cpu_thermal = "/soc/thermal-zones/cpu-thermal";
        cpu_passive = "/soc/thermal-zones/cpu-thermal/trips/cpu-passive";
        cpu_hot = "/soc/thermal-zones/cpu-thermal/trips/cpu-hot";
        cpu_critical = "/soc/thermal-zones/cpu-thermal/trips/cpu-critical";
        ddr_thermal = "/soc/thermal-zones/ddr-thermal";
        ddr_passive = "/soc/thermal-zones/ddr-thermal/trips/ddr-passive";
        ddr_critical = "/soc/thermal-zones/ddr-thermal/trips/ddr-critical";
        ethmac = "/soc/ethernet@ff3f0000";
        mdio0 = "/soc/ethernet@ff3f0000/mdio";
        apb = "/soc/bus@ff600000";
        hdmi_tx = "/soc/bus@ff600000/hdmi-tx@0";
        hdmi_tx_venc_port = "/soc/bus@ff600000/hdmi-tx@0/port@0";
        hdmi_tx_in = "/soc/bus@ff600000/hdmi-tx@0/port@0/endpoint";
        hdmi_tx_tmds_port = "/soc/bus@ff600000/hdmi-tx@0/port@1";
        hdmi_tx_tmds_out = "/soc/bus@ff600000/hdmi-tx@0/port@1/endpoint";
        apb_efuse = "/soc/bus@ff600000/bus@30000";
        hwrng = "/soc/bus@ff600000/bus@30000/rng@218";
        acodec = "/soc/bus@ff600000/audio-controller@32000";
        periphs = "/soc/bus@ff600000/bus@34400";
        periphs_pinctrl = "/soc/bus@ff600000/bus@34400/pinctrl@40";
        gpio = "/soc/bus@ff600000/bus@34400/pinctrl@40/bank@40";
        cec_ao_a_h_pins = "/soc/bus@ff600000/bus@34400/pinctrl@40/cec_ao_a_h";
        cec_ao_b_h_pins = "/soc/bus@ff600000/bus@34400/pinctrl@40/cec_ao_b_h";
        emmc_ctrl_pins = "/soc/bus@ff600000/bus@34400/pinctrl@40/emmc-ctrl";
        emmc_data_4b_pins = "/soc/bus@ff600000/bus@34400/pinctrl@40/emmc-data-4b";
        emmc_data_8b_pins = "/soc/bus@ff600000/bus@34400/pinctrl@40/emmc-data-8b";
        emmc_ds_pins = "/soc/bus@ff600000/bus@34400/pinctrl@40/emmc-ds";
        emmc_clk_gate_pins = "/soc/bus@ff600000/bus@34400/pinctrl@40/emmc_clk_gate";
        hdmitx_ddc_pins = "/soc/bus@ff600000/bus@34400/pinctrl@40/hdmitx_ddc";
        hdmitx_hpd_pins = "/soc/bus@ff600000/bus@34400/pinctrl@40/hdmitx_hpd";
        i2c0_sda_c_pins = "/soc/bus@ff600000/bus@34400/pinctrl@40/i2c0-sda-c";
        i2c0_sck_c_pins = "/soc/bus@ff600000/bus@34400/pinctrl@40/i2c0-sck-c";
        i2c0_sda_z0_pins = "/soc/bus@ff600000/bus@34400/pinctrl@40/i2c0-sda-z0";
        i2c0_sck_z1_pins = "/soc/bus@ff600000/bus@34400/pinctrl@40/i2c0-sck-z1";
        i2c0_sda_z7_pins = "/soc/bus@ff600000/bus@34400/pinctrl@40/i2c0-sda-z7";
        i2c0_sda_z8_pins = "/soc/bus@ff600000/bus@34400/pinctrl@40/i2c0-sda-z8";
        i2c1_sda_x_pins = "/soc/bus@ff600000/bus@34400/pinctrl@40/i2c1-sda-x";
        i2c1_sck_x_pins = "/soc/bus@ff600000/bus@34400/pinctrl@40/i2c1-sck-x";
        i2c1_sda_h2_pins = "/soc/bus@ff600000/bus@34400/pinctrl@40/i2c1-sda-h2";
        i2c1_sck_h3_pins = "/soc/bus@ff600000/bus@34400/pinctrl@40/i2c1-sck-h3";
        i2c1_sda_h6_pins = "/soc/bus@ff600000/bus@34400/pinctrl@40/i2c1-sda-h6";
        i2c1_sck_h7_pins = "/soc/bus@ff600000/bus@34400/pinctrl@40/i2c1-sck-h7";
        i2c2_sda_x_pins = "/soc/bus@ff600000/bus@34400/pinctrl@40/i2c2-sda-x";
        i2c2_sck_x_pins = "/soc/bus@ff600000/bus@34400/pinctrl@40/i2c2-sck-x";
        i2c2_sda_z_pins = "/soc/bus@ff600000/bus@34400/pinctrl@40/i2c2-sda-z";
        i2c2_sck_z_pins = "/soc/bus@ff600000/bus@34400/pinctrl@40/i2c2-sck-z";
        i2c3_sda_h_pins = "/soc/bus@ff600000/bus@34400/pinctrl@40/i2c3-sda-h";
        i2c3_sck_h_pins = "/soc/bus@ff600000/bus@34400/pinctrl@40/i2c3-sck-h";
        i2c3_sda_a_pins = "/soc/bus@ff600000/bus@34400/pinctrl@40/i2c3-sda-a";
        i2c3_sck_a_pins = "/soc/bus@ff600000/bus@34400/pinctrl@40/i2c3-sck-a";
        mclk0_a_pins = "/soc/bus@ff600000/bus@34400/pinctrl@40/mclk0-a";
        mclk1_a_pins = "/soc/bus@ff600000/bus@34400/pinctrl@40/mclk1-a";
        mclk1_x_pins = "/soc/bus@ff600000/bus@34400/pinctrl@40/mclk1-x";
        mclk1_z_pins = "/soc/bus@ff600000/bus@34400/pinctrl@40/mclk1-z";
        nor_pins = "/soc/bus@ff600000/bus@34400/pinctrl@40/nor";
        pdm_din0_a_pins = "/soc/bus@ff600000/bus@34400/pinctrl@40/pdm-din0-a";
        pdm_din0_c_pins = "/soc/bus@ff600000/bus@34400/pinctrl@40/pdm-din0-c";
        pdm_din0_x_pins = "/soc/bus@ff600000/bus@34400/pinctrl@40/pdm-din0-x";
        pdm_din0_z_pins = "/soc/bus@ff600000/bus@34400/pinctrl@40/pdm-din0-z";
        pdm_din1_a_pins = "/soc/bus@ff600000/bus@34400/pinctrl@40/pdm-din1-a";
        pdm_din1_c_pins = "/soc/bus@ff600000/bus@34400/pinctrl@40/pdm-din1-c";
        pdm_din1_x_pins = "/soc/bus@ff600000/bus@34400/pinctrl@40/pdm-din1-x";
        pdm_din1_z_pins = "/soc/bus@ff600000/bus@34400/pinctrl@40/pdm-din1-z";
        pdm_din2_a_pins = "/soc/bus@ff600000/bus@34400/pinctrl@40/pdm-din2-a";
        pdm_din2_c_pins = "/soc/bus@ff600000/bus@34400/pinctrl@40/pdm-din2-c";
        pdm_din2_x_pins = "/soc/bus@ff600000/bus@34400/pinctrl@40/pdm-din2-x";
        pdm_din2_z_pins = "/soc/bus@ff600000/bus@34400/pinctrl@40/pdm-din2-z";
        pdm_din3_a_pins = "/soc/bus@ff600000/bus@34400/pinctrl@40/pdm-din3-a";
        pdm_din3_c_pins = "/soc/bus@ff600000/bus@34400/pinctrl@40/pdm-din3-c";
        pdm_din3_x_pins = "/soc/bus@ff600000/bus@34400/pinctrl@40/pdm-din3-x";
        pdm_din3_z_pins = "/soc/bus@ff600000/bus@34400/pinctrl@40/pdm-din3-z";
        pdm_dclk_a_pins = "/soc/bus@ff600000/bus@34400/pinctrl@40/pdm-dclk-a";
        pdm_dclk_c_pins = "/soc/bus@ff600000/bus@34400/pinctrl@40/pdm-dclk-c";
        pdm_dclk_x_pins = "/soc/bus@ff600000/bus@34400/pinctrl@40/pdm-dclk-x";
        pdm_dclk_z_pins = "/soc/bus@ff600000/bus@34400/pinctrl@40/pdm-dclk-z";
        pwm_a_pins = "/soc/bus@ff600000/bus@34400/pinctrl@40/pwm-a";
        pwm_b_x7_pins = "/soc/bus@ff600000/bus@34400/pinctrl@40/pwm-b-x7";
        pwm_b_x19_pins = "/soc/bus@ff600000/bus@34400/pinctrl@40/pwm-b-x19";
        pwm_c_c_pins = "/soc/bus@ff600000/bus@34400/pinctrl@40/pwm-c-c";
        pwm_c_x5_pins = "/soc/bus@ff600000/bus@34400/pinctrl@40/pwm-c-x5";
        pwm_c_x8_pins = "/soc/bus@ff600000/bus@34400/pinctrl@40/pwm-c-x8";
        pwm_d_x3_pins = "/soc/bus@ff600000/bus@34400/pinctrl@40/pwm-d-x3";
        pwm_d_x6_pins = "/soc/bus@ff600000/bus@34400/pinctrl@40/pwm-d-x6";
        pwm_e_pins = "/soc/bus@ff600000/bus@34400/pinctrl@40/pwm-e";
        pwm_f_x_pins = "/soc/bus@ff600000/bus@34400/pinctrl@40/pwm-f-x";
        pwm_f_h_pins = "/soc/bus@ff600000/bus@34400/pinctrl@40/pwm-f-h";
        sdcard_c_pins = "/soc/bus@ff600000/bus@34400/pinctrl@40/sdcard_c";
        sdcard_clk_gate_c_pins = "/soc/bus@ff600000/bus@34400/pinctrl@40/sdcard_clk_gate_c";
        sdcard_z_pins = "/soc/bus@ff600000/bus@34400/pinctrl@40/sdcard_z";
        sdcard_clk_gate_z_pins = "/soc/bus@ff600000/bus@34400/pinctrl@40/sdcard_clk_gate_z";
        sdio_pins = "/soc/bus@ff600000/bus@34400/pinctrl@40/sdio";
        sdio_clk_gate_pins = "/soc/bus@ff600000/bus@34400/pinctrl@40/sdio_clk_gate";
        spdif_in_a10_pins = "/soc/bus@ff600000/bus@34400/pinctrl@40/spdif-in-a10";
        spdif_in_a12_pins = "/soc/bus@ff600000/bus@34400/pinctrl@40/spdif-in-a12";
        spdif_in_h_pins = "/soc/bus@ff600000/bus@34400/pinctrl@40/spdif-in-h";
        spdif_out_h_pins = "/soc/bus@ff600000/bus@34400/pinctrl@40/spdif-out-h";
        spdif_out_a11_pins = "/soc/bus@ff600000/bus@34400/pinctrl@40/spdif-out-a11";
        spdif_out_a13_pins = "/soc/bus@ff600000/bus@34400/pinctrl@40/spdif-out-a13";
        spicc0_x_pins = "/soc/bus@ff600000/bus@34400/pinctrl@40/spicc0-x";
        spicc0_ss0_x_pins = "/soc/bus@ff600000/bus@34400/pinctrl@40/spicc0-ss0-x";
        spicc0_c_pins = "/soc/bus@ff600000/bus@34400/pinctrl@40/spicc0-c";
        spicc1_pins = "/soc/bus@ff600000/bus@34400/pinctrl@40/spicc1";
        spicc1_ss0_pins = "/soc/bus@ff600000/bus@34400/pinctrl@40/spicc1-ss0";
        tdm_a_din0_pins = "/soc/bus@ff600000/bus@34400/pinctrl@40/tdm-a-din0";
        tdm_a_din1_pins = "/soc/bus@ff600000/bus@34400/pinctrl@40/tdm-a-din1";
        tdm_a_dout0_pins = "/soc/bus@ff600000/bus@34400/pinctrl@40/tdm-a-dout0";
        tdm_a_dout1_pins = "/soc/bus@ff600000/bus@34400/pinctrl@40/tdm-a-dout1";
        tdm_a_fs_pins = "/soc/bus@ff600000/bus@34400/pinctrl@40/tdm-a-fs";
        tdm_a_sclk_pins = "/soc/bus@ff600000/bus@34400/pinctrl@40/tdm-a-sclk";
        tdm_a_slv_fs_pins = "/soc/bus@ff600000/bus@34400/pinctrl@40/tdm-a-slv-fs";
        tdm_a_slv_sclk_pins = "/soc/bus@ff600000/bus@34400/pinctrl@40/tdm-a-slv-sclk";
        tdm_b_din0_pins = "/soc/bus@ff600000/bus@34400/pinctrl@40/tdm-b-din0";
        tdm_b_din1_pins = "/soc/bus@ff600000/bus@34400/pinctrl@40/tdm-b-din1";
        tdm_b_din2_pins = "/soc/bus@ff600000/bus@34400/pinctrl@40/tdm-b-din2";
        tdm_b_din3_a_pins = "/soc/bus@ff600000/bus@34400/pinctrl@40/tdm-b-din3-a";
        tdm_b_din3_h_pins = "/soc/bus@ff600000/bus@34400/pinctrl@40/tdm-b-din3-h";
        tdm_b_dout0_pins = "/soc/bus@ff600000/bus@34400/pinctrl@40/tdm-b-dout0";
        tdm_b_dout1_pins = "/soc/bus@ff600000/bus@34400/pinctrl@40/tdm-b-dout1";
        tdm_b_dout2_pins = "/soc/bus@ff600000/bus@34400/pinctrl@40/tdm-b-dout2";
        tdm_b_dout3_a_pins = "/soc/bus@ff600000/bus@34400/pinctrl@40/tdm-b-dout3-a";
        tdm_b_dout3_h_pins = "/soc/bus@ff600000/bus@34400/pinctrl@40/tdm-b-dout3-h";
        tdm_b_fs_pins = "/soc/bus@ff600000/bus@34400/pinctrl@40/tdm-b-fs";
        tdm_b_sclk_pins = "/soc/bus@ff600000/bus@34400/pinctrl@40/tdm-b-sclk";
        tdm_b_slv_fs_pins = "/soc/bus@ff600000/bus@34400/pinctrl@40/tdm-b-slv-fs";
        tdm_b_slv_sclk_pins = "/soc/bus@ff600000/bus@34400/pinctrl@40/tdm-b-slv-sclk";
        tdm_c_din0_a_pins = "/soc/bus@ff600000/bus@34400/pinctrl@40/tdm-c-din0-a";
        tdm_c_din0_z_pins = "/soc/bus@ff600000/bus@34400/pinctrl@40/tdm-c-din0-z";
        tdm_c_din1_a_pins = "/soc/bus@ff600000/bus@34400/pinctrl@40/tdm-c-din1-a";
        tdm_c_din1_z_pins = "/soc/bus@ff600000/bus@34400/pinctrl@40/tdm-c-din1-z";
        tdm_c_din2_a_pins = "/soc/bus@ff600000/bus@34400/pinctrl@40/tdm-c-din2-a";
        eth_leds_pins = "/soc/bus@ff600000/bus@34400/pinctrl@40/eth-leds";
        eth_pins = "/soc/bus@ff600000/bus@34400/pinctrl@40/eth";
        eth_rgmii_pins = "/soc/bus@ff600000/bus@34400/pinctrl@40/eth-rgmii";
        tdm_c_din2_z_pins = "/soc/bus@ff600000/bus@34400/pinctrl@40/tdm-c-din2-z";
        tdm_c_din3_a_pins = "/soc/bus@ff600000/bus@34400/pinctrl@40/tdm-c-din3-a";
        tdm_c_din3_z_pins = "/soc/bus@ff600000/bus@34400/pinctrl@40/tdm-c-din3-z";
        tdm_c_dout0_a_pins = "/soc/bus@ff600000/bus@34400/pinctrl@40/tdm-c-dout0-a";
        tdm_c_dout0_z_pins = "/soc/bus@ff600000/bus@34400/pinctrl@40/tdm-c-dout0-z";
        tdm_c_dout1_a_pins = "/soc/bus@ff600000/bus@34400/pinctrl@40/tdm-c-dout1-a";
        tdm_c_dout1_z_pins = "/soc/bus@ff600000/bus@34400/pinctrl@40/tdm-c-dout1-z";
        tdm_c_dout2_a_pins = "/soc/bus@ff600000/bus@34400/pinctrl@40/tdm-c-dout2-a";
        tdm_c_dout2_z_pins = "/soc/bus@ff600000/bus@34400/pinctrl@40/tdm-c-dout2-z";
        tdm_c_dout3_a_pins = "/soc/bus@ff600000/bus@34400/pinctrl@40/tdm-c-dout3-a";
        tdm_c_dout3_z_pins = "/soc/bus@ff600000/bus@34400/pinctrl@40/tdm-c-dout3-z";
        tdm_c_fs_a_pins = "/soc/bus@ff600000/bus@34400/pinctrl@40/tdm-c-fs-a";
        tdm_c_fs_z_pins = "/soc/bus@ff600000/bus@34400/pinctrl@40/tdm-c-fs-z";
        tdm_c_sclk_a_pins = "/soc/bus@ff600000/bus@34400/pinctrl@40/tdm-c-sclk-a";
        tdm_c_sclk_z_pins = "/soc/bus@ff600000/bus@34400/pinctrl@40/tdm-c-sclk-z";
        tdm_c_slv_fs_a_pins = "/soc/bus@ff600000/bus@34400/pinctrl@40/tdm-c-slv-fs-a";
        tdm_c_slv_fs_z_pins = "/soc/bus@ff600000/bus@34400/pinctrl@40/tdm-c-slv-fs-z";
        tdm_c_slv_sclk_a_pins = "/soc/bus@ff600000/bus@34400/pinctrl@40/tdm-c-slv-sclk-a";
        tdm_c_slv_sclk_z_pins = "/soc/bus@ff600000/bus@34400/pinctrl@40/tdm-c-slv-sclk-z";
        uart_a_pins = "/soc/bus@ff600000/bus@34400/pinctrl@40/uart-a";
        uart_a_cts_rts_pins = "/soc/bus@ff600000/bus@34400/pinctrl@40/uart-a-cts-rts";
        uart_b_pins = "/soc/bus@ff600000/bus@34400/pinctrl@40/uart-b";
        uart_c_pins = "/soc/bus@ff600000/bus@34400/pinctrl@40/uart-c";
        uart_c_cts_rts_pins = "/soc/bus@ff600000/bus@34400/pinctrl@40/uart-c-cts-rts";
        cpu_temp = "/soc/bus@ff600000/temperature-sensor@34800";
        ddr_temp = "/soc/bus@ff600000/temperature-sensor@34c00";
        usb2_phy0 = "/soc/bus@ff600000/phy@36000";
        dmc = "/soc/bus@ff600000/bus@38000";
        canvas = "/soc/bus@ff600000/bus@38000/video-lut@48";
        usb2_phy1 = "/soc/bus@ff600000/phy@3a000";
        hiu = "/soc/bus@ff600000/bus@3c000";
        hhi = "/soc/bus@ff600000/bus@3c000/system-controller@0";
        clkc = "/soc/bus@ff600000/bus@3c000/system-controller@0/clock-controller";
        pwrc = "/soc/bus@ff600000/bus@3c000/system-controller@0/power-controller";
        usb3_pcie_phy = "/soc/bus@ff600000/phy@46000";
        eth_phy = "/soc/bus@ff600000/mdio-multiplexer@4c000";
        ext_mdio = "/soc/bus@ff600000/mdio-multiplexer@4c000/mdio@0";
        int_mdio = "/soc/bus@ff600000/mdio-multiplexer@4c000/mdio@1";
        internal_ephy = "/soc/bus@ff600000/mdio-multiplexer@4c000/mdio@1/ethernet-phy@8";
        pdm = "/soc/bus@ff600000/audio-controller@40000";
        audio = "/soc/bus@ff600000/bus@42000";
        clkc_audio = "/soc/bus@ff600000/bus@42000/clock-controller@0";
        toddr_a = "/soc/bus@ff600000/bus@42000/audio-controller@100";
        toddr_b = "/soc/bus@ff600000/bus@42000/audio-controller@140";
        toddr_c = "/soc/bus@ff600000/bus@42000/audio-controller@180";
        frddr_a = "/soc/bus@ff600000/bus@42000/audio-controller@1c0";
        frddr_b = "/soc/bus@ff600000/bus@42000/audio-controller@200";
        frddr_c = "/soc/bus@ff600000/bus@42000/audio-controller@240";
        arb = "/soc/bus@ff600000/bus@42000/reset-controller@280";
        tdmin_a = "/soc/bus@ff600000/bus@42000/audio-controller@300";
        tdmin_b = "/soc/bus@ff600000/bus@42000/audio-controller@340";
        tdmin_c = "/soc/bus@ff600000/bus@42000/audio-controller@380";
        tdmin_lb = "/soc/bus@ff600000/bus@42000/audio-controller@3c0";
        spdifin = "/soc/bus@ff600000/bus@42000/audio-controller@400";
        spdifout = "/soc/bus@ff600000/bus@42000/audio-controller@480";
        tdmout_a = "/soc/bus@ff600000/bus@42000/audio-controller@500";
        tdmout_b = "/soc/bus@ff600000/bus@42000/audio-controller@540";
        tdmout_c = "/soc/bus@ff600000/bus@42000/audio-controller@580";
        spdifout_b = "/soc/bus@ff600000/bus@42000/audio-controller@680";
        toacodec = "/soc/bus@ff600000/bus@42000/audio-controller@740";
        tohdmitx = "/soc/bus@ff600000/bus@42000/audio-controller@744";
        aobus = "/soc/bus@ff800000";
        rti = "/soc/bus@ff800000/sys-ctrl@0";
        clkc_AO = "/soc/bus@ff800000/sys-ctrl@0/clock-controller";
        ao_pinctrl = "/soc/bus@ff800000/sys-ctrl@0/pinctrl@14";
        gpio_ao = "/soc/bus@ff800000/sys-ctrl@0/pinctrl@14/bank@14";
        i2c_ao_sck_pins = "/soc/bus@ff800000/sys-ctrl@0/pinctrl@14/i2c_ao_sck_pins";
        i2c_ao_sda_pins = "/soc/bus@ff800000/sys-ctrl@0/pinctrl@14/i2c_ao_sda";
        i2c_ao_sck_e_pins = "/soc/bus@ff800000/sys-ctrl@0/pinctrl@14/i2c_ao_sck_e";
        i2c_ao_sda_e_pins = "/soc/bus@ff800000/sys-ctrl@0/pinctrl@14/i2c_ao_sda_e";
        mclk0_ao_pins = "/soc/bus@ff800000/sys-ctrl@0/pinctrl@14/mclk0-ao";
        tdm_ao_b_din0_pins = "/soc/bus@ff800000/sys-ctrl@0/pinctrl@14/tdm-ao-b-din0";
        spdif_ao_out_pins = "/soc/bus@ff800000/sys-ctrl@0/pinctrl@14/spdif-ao-out";
        tdm_ao_b_din1_pins = "/soc/bus@ff800000/sys-ctrl@0/pinctrl@14/tdm-ao-b-din1";
        tdm_ao_b_din2_pins = "/soc/bus@ff800000/sys-ctrl@0/pinctrl@14/tdm-ao-b-din2";
        tdm_ao_b_dout0_pins = "/soc/bus@ff800000/sys-ctrl@0/pinctrl@14/tdm-ao-b-dout0";
        tdm_ao_b_dout1_pins = "/soc/bus@ff800000/sys-ctrl@0/pinctrl@14/tdm-ao-b-dout1";
        tdm_ao_b_dout2_pins = "/soc/bus@ff800000/sys-ctrl@0/pinctrl@14/tdm-ao-b-dout2";
        tdm_ao_b_fs_pins = "/soc/bus@ff800000/sys-ctrl@0/pinctrl@14/tdm-ao-b-fs";
        tdm_ao_b_sclk_pins = "/soc/bus@ff800000/sys-ctrl@0/pinctrl@14/tdm-ao-b-sclk";
        tdm_ao_b_slv_fs_pins = "/soc/bus@ff800000/sys-ctrl@0/pinctrl@14/tdm-ao-b-slv-fs";
        tdm_ao_b_slv_sclk_pins = "/soc/bus@ff800000/sys-ctrl@0/pinctrl@14/tdm-ao-b-slv-sclk";
        uart_ao_a_pins = "/soc/bus@ff800000/sys-ctrl@0/pinctrl@14/uart-a-ao";
        uart_ao_a_cts_rts_pins = "/soc/bus@ff800000/sys-ctrl@0/pinctrl@14/uart-ao-a-cts-rts";
        pwm_a_e_pins = "/soc/bus@ff800000/sys-ctrl@0/pinctrl@14/pwm-a-e";
        pwm_ao_a_pins = "/soc/bus@ff800000/sys-ctrl@0/pinctrl@14/pwm-ao-a";
        pwm_ao_b_pins = "/soc/bus@ff800000/sys-ctrl@0/pinctrl@14/pwm-ao-b";
        pwm_ao_c_4_pins = "/soc/bus@ff800000/sys-ctrl@0/pinctrl@14/pwm-ao-c-4";
        pwm_ao_c_6_pins = "/soc/bus@ff800000/sys-ctrl@0/pinctrl@14/pwm-ao-c-6";
        pwm_ao_d_5_pins = "/soc/bus@ff800000/sys-ctrl@0/pinctrl@14/pwm-ao-d-5";
        pwm_ao_d_10_pins = "/soc/bus@ff800000/sys-ctrl@0/pinctrl@14/pwm-ao-d-10";
        pwm_ao_d_e_pins = "/soc/bus@ff800000/sys-ctrl@0/pinctrl@14/pwm-ao-d-e";
        remote_input_ao_pins = "/soc/bus@ff800000/sys-ctrl@0/pinctrl@14/remote-input-ao";
        vrtc = "/soc/bus@ff800000/rtc@a8";
        cec_AO = "/soc/bus@ff800000/cec@100";
        sec_AO = "/soc/bus@ff800000/ao-secure@140";
        cecb_AO = "/soc/bus@ff800000/cec@280";
        pwm_AO_cd = "/soc/bus@ff800000/pwm@2000";
        uart_AO = "/soc/bus@ff800000/serial@3000";
        uart_AO_B = "/soc/bus@ff800000/serial@4000";
        i2c_AO = "/soc/bus@ff800000/i2c@5000";
        pwm_AO_ab = "/soc/bus@ff800000/pwm@7000";
        ir = "/soc/bus@ff800000/ir@8000";
        saradc = "/soc/bus@ff800000/adc@9000";
        vdec = "/soc/video-decoder@ff620000";
        vpu = "/soc/vpu@ff900000";
        cvbs_vdac_port = "/soc/vpu@ff900000/port@0";
        cvbs_vdac_out = "/soc/vpu@ff900000/port@0/endpoint";
        hdmi_tx_port = "/soc/vpu@ff900000/port@1";
        hdmi_tx_out = "/soc/vpu@ff900000/port@1/endpoint";
        gic = "/soc/interrupt-controller@ffc01000";
        cbus = "/soc/bus@ffd00000";
        reset = "/soc/bus@ffd00000/reset-controller@1004";
        gpio_intc = "/soc/bus@ffd00000/interrupt-controller@f080";
        watchdog = "/soc/bus@ffd00000/watchdog@f0d0";
        spicc0 = "/soc/bus@ffd00000/spi@13000";
        spicc1 = "/soc/bus@ffd00000/spi@15000";
        spifc = "/soc/bus@ffd00000/spi@14000";
        pwm_ef = "/soc/bus@ffd00000/pwm@19000";
        pwm_cd = "/soc/bus@ffd00000/pwm@1a000";
        pwm_ab = "/soc/bus@ffd00000/pwm@1b000";
        i2c3 = "/soc/bus@ffd00000/i2c@1c000";
        i2c2 = "/soc/bus@ffd00000/i2c@1d000";
        i2c1 = "/soc/bus@ffd00000/i2c@1e000";
        i2c0 = "/soc/bus@ffd00000/i2c@1f000";
        clk_msr = "/soc/bus@ffd00000/clock-measure@18000";
        uart_C = "/soc/bus@ffd00000/serial@22000";
        uart_B = "/soc/bus@ffd00000/serial@23000";
        uart_A = "/soc/bus@ffd00000/serial@24000";
        sd_emmc_a = "/soc/sd@ffe03000";
        sd_emmc_b = "/soc/sd@ffe05000";
        sd_emmc_c = "/soc/mmc@ffe07000";
        usb = "/soc/usb@ffe09000";
        dwc2 = "/soc/usb@ffe09000/usb@ff400000";
        dwc3 = "/soc/usb@ffe09000/usb@ff500000";
        mali = "/soc/gpu@ffe40000";
        xtal = "/xtal-clk";
        tdmif_a = "/audio-controller-0";
        tdmif_b = "/audio-controller-1";
        tdmif_c = "/audio-controller-2";
        cpu0 = "/cpus/cpu@0";
        cpu1 = "/cpus/cpu@1";
        cpu2 = "/cpus/cpu@2";
        cpu3 = "/cpus/cpu@3";
        l2 = "/cpus/l2-cache0";
        cpu_opp_table = "/opp-table";
        spdif_dit = "/audio-codec-1";
        cvbs_connector_in = "/cvbs-connector/port/endpoint";
        emmc_pwrseq = "/emmc-pwrseq";
        hdmi_connector_in = "/hdmi-connector/port/endpoint";
        flash_1v8 = "/regulator-flash_1v8";
        main_12v = "/regulator-main_12v";
        usb_pwr_en = "/regulator-usb_pwr_en";
        vcc_1v8 = "/regulator-vcc_1v8";
        vcc_3v3 = "/regulator-vcc_3v3";
        vcc_5v = "/regulator-vcc_5v";
        vddao_1v8 = "/regulator-vddao_1v8";
        vddao_3v3 = "/regulator-vddao_3v3";
        vddcpu = "/regulator-vddcpu";
        vddgpu = "/regulator-vddgpu";
        wifi32k = "/wifi32k";
        sdio_pwrseq = "/sdio-pwrseq";
    };
    bt-dev {
        compatible = "amlogic,bt-dev";
        dev_name = "bt-dev";
        status = "okay";
        gpio_reset = <0x00000034 0x00000051 0x00000000>;
    };
    wifi {
        dev_name = "aml_wifi";
        interrupt_pin = <0x00000034 0x00000052 0x00000000>;
        interrupts = <0x00000000 0x0000004d 0x00000004>;
        power_on_pin = <0x00000034 0x00000046 0x00000000>;
        dhd_static_buf;
        pinctrl-names = "default";
        pinctrl-0 = <0x00000095>;
        pwm_config = <0x00002000>;
        compatible = "amlogic,uwe5621-irq";
        status = "okay";
        irq_trigger_type = "GPIO_IRQ_HIGH";
    };
    wifi_pwm_conf {
        phandle = <0x00002000>;
        pwm_channel1_conf {
            pwms = <0x00000119 0x00000000 0x0000774d 0x00000000>;
            duty-cycle = <0x00003ba6>;
            times = <0x0000000a>;
        };
        pwm_channel2_conf {
            pwms = <0x00000119 0x00000002 0x00007724 0x00000000>;
            duty-cycle = <0x00003b92>;
            times = <0x0000000c>;
        };
    };
    wifi32k {
        compatible = "pwm-clock";
        #clock-cells = <0x00000000>;
        clock-frequency = <0x00008000>;
        pwms = <0x00000119 0x00000000 0x00007736 0x00000000>;
        phandle = <0x00002001>;
    };
    sdio-pwrseq {
        compatible = "mmc-pwrseq-simple";
        reset-gpios = <0x00000034 0x00000046 0x00000001>;
        post-power-on-delay-ms = <0x000003e8>;
        power-off-delay-us = <0x00002710>;
        clocks = <0x00002001>;
        clock-names = "ext_clock";
        phandle = <0x00002002>;
    };
};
